[part 3 of 3]
AUTOSAR XML (schema 00044)
package /Continental_08/PowerSAR/StdSrvIf_Dem_AR430_V100/ImplementationDataTypes
  10 x impl type:
    Dem_DebounceResetStatusType: compu {0=DEM_DEBOUNCE_STATUS_FREEZE, 1=DEM_DEBOUNCE_STATUS_RESET}, implementation-data-type=uint8
    Dem_DebouncingStateType: compu {1=DEM_TEMPORARILY_DEFECTIVE, 2=DEM_FINALLY_DEFECTIVE, 4=DEM_TEMPORARILY_HEALED, 8=DEM_TEST_COMPLETE, 16=DEM_DTR_UPDATE}, implementation-data-type=uint8
    Dem_DTCFormatType: compu {0=DEM_DTC_FORMAT_OBD, 1=DEM_DTC_FORMAT_UDS, 2=DEM_DTC_FORMAT_J1939}, implementation-data-type=uint8
    Dem_DTRControlType: compu {0=DEM_DTR_CTL_NORMAL, 1=DEM_DTR_CTL_NO_MAX, 2=DEM_DTR_CTL_NO_MIN, 3=DEM_DTR_CTL_RESET, 4=DEM_DTR_CTL_INVISIBLE}, implementation-data-type=uint8
    Dem_EventStatusType: compu {0=DEM_EVENT_STATUS_PASSED, 1=DEM_EVENT_STATUS_FAILED, 2=DEM_EVENT_STATUS_PREPASSED, 3=DEM_EVENT_STATUS_PREFAILED, 4=DEM_EVENT_STATUS_FDC_THRESHOLD_REACHED}, implementation-data-type=uint8
    Dem_InitMonitorReasonType: compu {1=DEM_INIT_MONITOR_CLEAR, 2=DEM_INIT_MONITOR_RESTART, 3=DEM_INIT_MONITOR_REENABLED, 4=DEM_INIT_MONITOR_STORAGE_REENABLED}, implementation-data-type=uint8
    Dem_MaxDataValueType: category=ARRAY
      element DimX: array-size=ScNrByteBufFrfDem, array-size-semantics=FIXED-SIZE, implementation-data-type=uint8
    Dem_MonitorStatusType: compu {1=DEM_MONITOR_STATUS_TF, 2=DEM_MONITOR_STATUS_TNCTOC}, implementation-data-type=uint8
    Dem_OperationCycleStateType: compu {0=DEM_CYCLE_STATE_START, 1=DEM_CYCLE_STATE_END}, implementation-data-type=uint8
    Dem_UdsStatusByteType: compu {1=DEM_UDS_STATUS_TF, 2=DEM_UDS_STATUS_TFTOC, 4=DEM_UDS_STATUS_PDTC, 8=DEM_UDS_STATUS_CDTC, 16=DEM_UDS_STATUS_TNCSLC, 32=DEM_UDS_STATUS_TFSLC, 64=DEM_UDS_STATUS_TNCTOC, 128=DEM_UDS_STATUS_WIR}, implementation-data-type=uint8
package /Continental_08/PowerSAR/StdSrvIf_Dem_AR430_V100/PortInterfaces/V1_0_0
  6 x client server interface, all with is-service=true:
    CallbackClearEventAllowed  # Gets the permission before clearing a specific event from the SW-C
      operation ClearEventAllowed: possible-error=[CallbackClearEventAllowed/E_NOT_OK, CallbackClearEventAllowed/E_OK]  # Gets the permission to clear a specific event
        arg Allowed: type=boolean, direction=OUT, server-argument-impl-policy=USE-ARGUMENT-TYPE  # True - clearance of event is allowed, False - clearance of event is not allowed
      error E_NOT_OK: error-code=1
      error E_OK: error-code=0
    CycleQualified  # Provides the capability to get and set the qualification state of the dependent operation cycle
      operation GetCycleQualified: possible-error=[CycleQualified/E_NOT_OK, CycleQualified/E_OK]  # Returns the qualification state of the dependent operation cycle. Always E_OK is returned.
        arg isQualified: type=boolean, direction=OUT, server-argument-impl-policy=USE-ARGUMENT-TYPE  # TRUE: The dependent operation cylcle is qualified. FALSE: The qualification conditions of the dependent operation cylcle have not been met.
      operation SetCycleQualified: possible-error=[CycleQualified/E_NOT_OK, CycleQualified/E_OK]  # Sets a dependent operation cycle as qualified, so it may be processed along with its leading cycle. Always E_OK is returned.
      error E_NOT_OK: error-code=1
      error E_OK: error-code=0
    DTRCentralReport  # Provides the capability to report a DTR result
      operation SetDTR: possible-error=[DTRCentralReport/E_NOT_OK, DTRCentralReport/E_OK]  # Reports a DTR result with lower and upper limit. E_NOT_OK: Report of DTR result failed
        4 x arg, all with direction=IN, server-argument-impl-policy=USE-ARGUMENT-TYPE:
          TestResult: type=sint32  # Test result of DTR
          LowerLimit: type=sint32  # Lower limit of DTR
          UpperLimit: type=sint32  # Upper limit of DTR
          Ctrlval: type=Dem_DTRControlType  # Control value of the DTR to support its interpretation Dem-internally
      error E_NOT_OK: error-code=1
      error E_OK: error-code=0
    EnableCondition  # Provides the capability to set an enable condition
      operation SetEnableCondition: possible-error=[EnableCondition/E_NOT_OK, EnableCondition/E_OK]  # Sets an enable condition. E_NOT_OK: the setting of the enable condition failed
        arg ConditionFulfilled: type=boolean, direction=IN, server-argument-impl-policy=USE-ARGUMENT-TYPE  # Specifies whether the enable condition is fulfilled (TRUE) or not fulfilled (FALSE)
      error E_NOT_OK: error-code=1
      error E_OK: error-code=0
    EventAvailable  # Provides the capability to control the available status of an event
      operation SetEventAvailable: possible-error=[EventAvailable/E_NOT_OK, EventAvailable/E_OK]  # Set the available status of a specific event. E_NOT_OK: change of available status not accepted
        arg AvailableStatus: type=boolean, direction=IN, server-argument-impl-policy=USE-ARGUMENT-TYPE  # Specifies whether the respective event shall be available (TRUE) or not (FALSE)
      error E_NOT_OK: error-code=1
      error E_OK: error-code=0
    OperationCycle  # Provides the capability to set the state of an operation cycle
      operation GetOperationCycleState: possible-error=[OperationCycle/E_NOT_OK, OperationCycle/E_OK]  # Gets information about the status of a specific operation cycle
        arg CycleState: type=Dem_OperationCycleStateType, direction=OUT, server-argument-impl-policy=USE-ARGUMENT-TYPE  # Cycle status information
      operation SetOperationCycleState: possible-error=[OperationCycle/E_NOT_OK, OperationCycle/E_OK]  # Sets an operation cycle state. The interface has an asynchronous behavior. The asynchronous acknowledgements are the related InitMonitorForEvent callbacks.
        arg CycleState: type=Dem_OperationCycleStateType, direction=IN, server-argument-impl-policy=USE-ARGUMENT-TYPE  # New operation cycle state: (re-)start or end
      error E_NOT_OK: error-code=1
      error E_OK: error-code=0
package /Continental_08/PowerSAR/StdSrvIf_Dem_AR430_V100/PortInterfaces/V2_0_0
  5 x client server interface, all with is-service=true:
    CallbackGetFaultDetectCounter  # Gets the monitor-internal fault detection counter value of a specific event from the SW-C
      operation GetFaultDetectionCounter: possible-error=[CallbackGetFaultDetectCounter/E_NOT_OK, CallbackGetFaultDetectCounter/E_OK]  # Gets the current fault detection counter value
        arg FaultDetectionCounter: type=sint8, direction=OUT, server-argument-impl-policy=USE-ARGUMENT-TYPE  # This parameter receives the fault detection counter information of the requested EventId. If the return value of the function call is other than E_OK this parameter does not contain valid data. Range: -128...127 PASSED...FAILED according to ISO 14229-1
      error E_NOT_OK: error-code=1
      error E_OK: error-code=0
    CallbackInitMonitorForEvent  # Triggers an event-specific initialization of the monitor part of the SW-C
      operation InitMonitorForEvent: possible-error=[CallbackInitMonitorForEvent/E_NOT_OK, CallbackInitMonitorForEvent/E_OK]  # Initializes the diagnostic monitor of a specific event. Return value shall be always E_OK.
        arg InitMonitorReason: type=Dem_InitMonitorReasonType, direction=IN, server-argument-impl-policy=USE-ARGUMENT-TYPE  # Specific (re-)initialization reason evaluated from the monitor to identify the initialization kind to be performed
      error E_NOT_OK: error-code=1
      error E_OK: error-code=0
    DiagnosticMonitor  # Provides the capability to modify the event information
      6 x operation, all with possible-error=[DiagnosticMonitor/E_NOT_OK, DiagnosticMonitor/E_OK]:
        ClearPrestoredFreezeFrame  # Clears a prestored freeze frame of a specific event.
        PrestoreFreezeFrame  # Captures the freeze frame data for a specific event.
        ResetEventDebounceStatus  # Controls the internal debounce counter/timer. The event qualification will not be affected by these debounce state changes. E_NOT_OK: Only on development error
          arg DebounceResetStatus: type=Dem_DebounceResetStatusType, direction=IN, server-argument-impl-policy=USE-ARGUMENT-TYPE  # Freeze or reset the internal debounce counter/timer of the specified event
        ResetEventStatus  # Resets the event failed status. E_NOT_OK: reset of event status failed or is not allowed, because the event is already tested in this operation cycle
        SetEventDisabled  # Service for reporting the event as disabled to the Dem for the PID $41 computation.
        SetEventStatus  # Processes the events reported by SW-Cs via RTE. E_NOT_OK: set of event status failed or could not be accepted (e.g.: the operation cycle configured for this event has not been started, an according enable condition has been disabled)
          arg EventStatus: type=Dem_EventStatusType, direction=IN, server-argument-impl-policy=USE-ARGUMENT-TYPE  # Monitor test result
      error E_NOT_OK: error-code=1
      error E_OK: error-code=0
    IUMPRDenominator  # Provides the capability to define the number of times the vehicle operation has been fulfilled
      operation RepIUMPRDenLock: possible-error=[IUMPRDenominator/E_NOT_OK, IUMPRDenominator/E_OK]  # Service is used to lock a denominator of a specific monitor.
      operation RepIUMPRDenRelease: possible-error=[IUMPRDenominator/E_NOT_OK, IUMPRDenominator/E_OK]  # Service is used to release a denominator of a specific monitor.
      error E_NOT_OK: error-code=1
      error E_OK: error-code=0
    IUMPRNumerator  # Provides the capability to define the number of times a fault could have been found
      operation RepIUMPRFaultDetect: possible-error=[IUMPRNumerator/E_NOT_OK, IUMPRNumerator/E_OK]  # Service for reporting that faults are possibly found because all conditions are fullfilled.
      error E_NOT_OK: error-code=1
      error E_OK: error-code=0
package /Continental_08/PowerSAR/StdSrvIf_Dem_AR430_V100/PortInterfaces/V3_0_0
  client server interface DiagnosticInfo: is-service=true  # Provides the capability to obtain the event information
    7 x operation:
      GetDebouncingOfEvent: possible-error=[DiagnosticInfo/E_NOT_OK, DiagnosticInfo/E_OK]  # Gets the debouncing status of an event. This function shall not be used for events with native debouncing within their functions. It is rather for events using debouncing within the Dem.
        arg DebouncingState: type=Dem_DebouncingStateType, direction=OUT, server-argument-impl-policy=USE-ARGUMENT-TYPE  # Bit 0 temporarily defective (0 < FDC < 127), Bit 1 finally defective (FDC = 127), Bit 2 temporarily healed (-128 < FDC < 0), Bit 3 test complete (FDC = -128 or 127), Bit 4 DTR update (test && debouncing complete && enable/storage conditions fulfilled)
      GetDTCOfEvent: possible-error=[DEM_E_NO_DTC_AVAILABLE, DiagnosticInfo/E_NOT_OK, DiagnosticInfo/E_OK]  # Gets the DTC of an event. DEM_E_NO_DTC_AVAILABLE: there is no DTC configured in the requested format
        arg DTCFormat: type=Dem_DTCFormatType, direction=IN, server-argument-impl-policy=USE-ARGUMENT-TYPE  # Defines the output-format of the requested DTC value
        arg DTCOfEvent: type=uint32, direction=OUT, server-argument-impl-policy=USE-ARGUMENT-TYPE  # Receives the DTC value in respective format returned by this function. If the return value of the function is other than E_OK this parameter does not contain valid data.
      GetEventExtendedDataRecordEx: possible-error=[DEM_BUFFER_TOO_SMALL, DEM_NO_SUCH_ELEMENT, DiagnosticInfo/E_NOT_OK, DiagnosticInfo/E_OK]  # Gets the data of an extended data record by event. DEM_BUFFER_TOO_SMALL: The provided buffer size is too small. DEM_NO_SUCH_ELEMENT: The requested event data is not currently stored or the requested record number is not supported by the event or the requested DID is not supported by the freeze frame.
        arg RecordNumber: type=uint8, direction=IN, server-argument-impl-policy=USE-ARGUMENT-TYPE  # Identification of requested Extended data record. Valid values are between 0x01 and 0xEF as defined in ISO14229-1.
        arg DestBuffer: type=Dem_MaxDataValueType, direction=OUT, server-argument-impl-policy=USE-ARRAY-BASE-TYPE  # This parameter contains a byte pointer that points to the buffer, to which the extended data shall be written to. The format is raw hexadecimal values and contains no header-information.
        arg BufSize: type=uint16, direction=INOUT, server-argument-impl-policy=USE-ARGUMENT-TYPE  # When the function is called this parameter contains the maximum number of data bytes that can be written to the buffer. The function returns the actual number of written data bytes in this parameter.
      GetEventFreezeFrameDataEx: possible-error=[DEM_BUFFER_TOO_SMALL, DEM_NO_SUCH_ELEMENT, DiagnosticInfo/E_NOT_OK, DiagnosticInfo/E_OK]  # Gets the data of a freeze frame by event. DEM_BUFFER_TOO_SMALL: The provided buffer size is too small. DEM_NO_SUCH_ELEMENT: The requested event data is not currently stored or the requested record number is not supported by the event or the requested DID is not supported by the freeze frame.
        4 x arg:
          RecordNumber: type=uint8, direction=IN, server-argument-impl-policy=USE-ARGUMENT-TYPE  # This parameter is a unique identifier for a freeze frame record as defined in ISO14229-1. 0xFF means most recent freeze frame record is returned. 0x00 is only supported if the Dem module supports WWH-OBD.
          DataId: type=uint16, direction=IN, server-argument-impl-policy=USE-ARGUMENT-TYPE  # This parameter specifies the DID (ISO14229-1) that shall be copied to the destination buffer.
          DestBuffer: type=Dem_MaxDataValueType, direction=OUT, server-argument-impl-policy=USE-ARRAY-BASE-TYPE  # This parameter contains a byte pointer that points to the buffer, to which the freeze frame data record shall be written to. The format is raw hexadecimal values and contains no header-information.
          BufSize: type=uint16, direction=INOUT, server-argument-impl-policy=USE-ARGUMENT-TYPE  # When the function is called this parameter contains the maximum number of data bytes that can be written to the buffer. The function returns the actual number of written data bytes in this parameter.
      GetEventUdsStatus: possible-error=[DiagnosticInfo/E_NOT_OK, DiagnosticInfo/E_OK]  # Gets the current UDS status byte assigned to the DTC for the event
        arg UDSStatusByte: type=Dem_UdsStatusByteType, direction=OUT, server-argument-impl-policy=USE-ARGUMENT-TYPE  # UDS DTC status byte of the requested event. If the return value of the function call is E_NOT_OK, this parameter does not contain valid data.
      GetFaultDetectionCounter: possible-error=[DEM_E_NO_FDC_AVAILABLE, DiagnosticInfo/E_NOT_OK, DiagnosticInfo/E_OK]  # Gets the current fault detection counter value. DEM_E_NO_FDC_AVAILABLE: there is no fault detection counter available for the requested event.
        arg FaultDetectionCounter: type=sint8, direction=OUT, server-argument-impl-policy=USE-ARGUMENT-TYPE  # This parameter receives the fault detection counter information of the requested EventId. If the return value of the function call is other than E_OK this parameter does not contain valid data. Range: -128...127 PASSED...FAILED according to ISO 14229-1
      GetMonitorStatus: possible-error=[DiagnosticInfo/E_NOT_OK, DiagnosticInfo/E_OK]  # Gets the current monitor status for an event. E_NOT_OK: getting the monitor status failed (e.g. an invalid event id was provided).
        arg MonitorStatus: type=Dem_MonitorStatusType, direction=OUT, server-argument-impl-policy=USE-ARGUMENT-TYPE  # Monitor status byte of the requested event. If the return value of the function call is E_NOT_OK, this parameter does not contain valid data.
    6 x error:
      DEM_BUFFER_TOO_SMALL: error-code=21
      DEM_E_NO_DTC_AVAILABLE: error-code=10
      DEM_E_NO_FDC_AVAILABLE: error-code=14
      DEM_NO_SUCH_ELEMENT: error-code=48
      E_NOT_OK: error-code=1
      E_OK: error-code=0
package /Continental_08/PowerSAR/StdSrvIf_FiM_AR422_V100/PortInterfaces/V2_0_0
  client server interface FunctionInhibition: is-service=true  # Service to query for the permission to execute a certain functionality represented by a FID.
    operation GetFunctionPermission: possible-error=[FunctionInhibition/E_NOT_OK, FunctionInhibition/E_OK]  # Get the permission state of the respective FID. E_NOT_OK: The request is not accepted, ie. initialization of FIM not completed
      arg Permission: type=boolean, direction=OUT, server-argument-impl-policy=USE-ARGUMENT-TYPE  # The permission of the requested FID. TRUE: FID has permission to run. FALSE: FID has no permission to run, i.e. shall not be executed.
    error E_NOT_OK: error-code=1
    error E_OK: error-code=0
package /Continental_08/PowerSAR/StdSrvIf_NvM_AR422_V100/ImplementationDataTypes
  impl type NvM_RequestResultType: compu {0=NVM_REQ_OK, 1=NVM_REQ_NOT_OK, 2=NVM_REQ_PENDING, 3=NVM_REQ_INTEGRITY_FAILED, 4=NVM_REQ_BLOCK_SKIPPED, 5=NVM_REQ_NV_INVALIDATED, 6=NVM_REQ_CANCELED, 7=NVM_REQ_REDUNDANCY_FAILED, 8=NVM_REQ_RESTORED_FROM_ROM}, implementation-data-type=uint8
package /Continental_08/PowerSAR/StdSrvIf_NvM_AR422_V100/PortInterfaces/V2_0_0
  client server interface NvMNotifyInitBlock  # Callback that is called by the NvM module when default data needs to be restored to the RAM image
    operation InitBlock: possible-error=NvMNotifyInitBlock/E_OK  # This callback is called if the initialization of a block has completed.
    error E_OK: error-code=0
  client server interface NvMNotifyJobFinished  # Callback that is called when a job has finished
    operation JobFinished: possible-error=NvMNotifyJobFinished/E_OK  # Callback that gets called if a job has finished
      arg ServiceId: type=uint8, direction=IN, server-argument-impl-policy=USE-ARGUMENT-TYPE  # Unique Service ID of NVRAM manager service
      arg JobResult: type=NvM_RequestResultType, direction=IN, server-argument-impl-policy=USE-ARGUMENT-TYPE  # Covers the job result of the previous processed single block job
    error E_OK: error-code=0
  client server interface NvMService  # The NvMService interface provides all main single block operations.
    12 x operation, all with possible-error=[NvMService/E_NOT_OK, NvMService/E_OK]:
      EraseBlock  # Service to erase a NV block.
      GetDataIndex  # Service for getting the currently set DataIndex of a dataset NVRAM block.
        arg DataIndexPtr: type=uint8, direction=OUT, server-argument-impl-policy=USE-ARGUMENT-TYPE  # Pointer to where to store the current dataset index (0..255)
      GetErrorStatus  # Service to read the block dependent error status information.
        arg RequestResultPtr: type=NvM_RequestResultType, direction=OUT, server-argument-impl-policy=USE-ARGUMENT-TYPE  # Pointer to where to store the request result
      InvalidateNvBlock  # Service to invalidate a NV block.
      ReadBlock  # Service to copy the data of the NV block to its corresponding RAM block.
        arg DstPtr: type=VoidPtr, direction=IN, server-argument-impl-policy=USE-ARGUMENT-TYPE  # Pointer to the RAM data block. It shall be set to NULL_PTR, if the RAM block is managed by the RTE through a NvBlockSwComponent.
      ReadPRAMBlock  # Service to copy the data of the NV block to its corresponding RAM block.
      RestoreBlockDefaults  # Service to restore the default data to its corresponding RAM block.
        arg DstPtr: type=VoidPtr, direction=IN, server-argument-impl-policy=USE-ARGUMENT-TYPE  # Pointer to the RAM data block. It shall be set to NULL_PTR, if the RAM block is managed by the RTE through a NvBlockSwComponent.
      RestorePRAMBlockDefaults  # Service to restore the default data to its corresponding RAM block.
      SetDataIndex  # Service for setting the DataIndex of a dataset NVRAM block.
        arg DataIndex: type=uint8, direction=IN, server-argument-impl-policy=USE-ARGUMENT-TYPE  # Index position (association) of a NV or ROM block
      SetRamBlockStatus  # Service for setting the RAM block status of an NVRAM block.
        arg BlockChanged: type=boolean, direction=IN, server-argument-impl-policy=USE-ARGUMENT-TYPE  # TRUE - validate the RAM block and mark block as changed, FALSE - invalidate the RAM block and mark block as unchanged
      WriteBlock  # Service to copy the data of the RAM block to its corresponding NV block.
        arg SrcPtr: type=ConstVoidPtr, direction=IN, server-argument-impl-policy=USE-ARGUMENT-TYPE  # Pointer to the RAM data block. It shall be set to NULL_PTR, if the RAM block is managed by the RTE through a NvBlockSwComponent.
      WritePRAMBlock  # Service to copy the data of the RAM block to its corresponding NV block.
    error E_NOT_OK: error-code=1
    error E_OK: error-code=0
package /Continental_08/PowerSAR/StdSrvIf_WdgM_AR430_V100/ImplementationDataTypes
  impl type WdgM_LocalStatusType: compu {0=WDGM_LOCAL_STATUS_OK, 1=WDGM_LOCAL_STATUS_FAILED, 2=WDGM_LOCAL_STATUS_EXPIRED, 4=WDGM_LOCAL_STATUS_DEACTIVATED}, implementation-data-type=uint8
package /Continental_08/PowerSAR/StdSrvIf_WdgM_AR430_V100/PortInterfaces/V1_0_0
  client server interface WdgM_LocalSupervision: is-service=true  # Supervision interface of one supervised entity checkpoint
    operation CheckpointReached: possible-error=[WdgM_LocalSupervision/E_NOT_OK, WdgM_LocalSupervision/E_OK]  # Indicates to the Watchdog Manager that a Checkpoint within a Supervised Entity has been reached
    error E_NOT_OK: error-code=1
    error E_OK: error-code=0
  client server interface WdgM_LocalSupervisionStatus: is-service=true  # Supervision status interface of one supervised entity
    operation GetLocalStatus: possible-error=[WdgM_LocalSupervisionStatus/E_NOT_OK, WdgM_LocalSupervisionStatus/E_OK]  # Returns the supervision status of an individual Supervised Entity
      arg Status: type=WdgM_LocalStatusType, direction=OUT, server-argument-impl-policy=USE-ARGUMENT-TYPE  # Supervision status of the given supervised entity
    error E_NOT_OK: error-code=1
    error E_OK: error-code=0
package /Continental_08/PowerSAR/Pcpt_BPL2AR  # Adaptation module for bus communication in receive direction
  complex device driver sw component type BPL2AR  # Adaptation module for bus communication in receive direction
    24 x provide/require port:
      PR_FacKpTqEmDynAjExt: nonqueued-sender-com-spec{data-element=FacKpTqEmDynAjExt, init-value=0 Nm*s}, provided-required-interface=FacKpTqEmDynAjExt  # External amplification factor for dynamic electrical machine torque path of anti-jerk
      PR_LvAjActExt: nonqueued-sender-com-spec{data-element=LvAjActExt, init-value=FALSE}, provided-required-interface=LvAjActExt  # External anti-jerk active
      PR_LvSleepReqVeh: nonqueued-sender-com-spec{data-element=LvSleepReqVeh, init-value=FALSE}, provided-required-interface=LvSleepReqVeh  # Sleep requested from vehicle
      PR_LvStOpmEmCtlNActReqClu: nonqueued-sender-com-spec{data-element=LvStOpmEmCtlNActReqClu, init-value=FALSE}, provided-required-interface=LvStOpmEmCtlNActReqClu  # Clutch is requesting to activate speed control
      PR_LvStOpmEmCtlTqActReqClu: nonqueued-sender-com-spec{data-element=LvStOpmEmCtlTqActReqClu, init-value=FALSE}, provided-required-interface=LvStOpmEmCtlTqActReqClu  # Clutch is requesting to activate torque control
      PR_LvUHvsReqExtEna: nonqueued-sender-com-spec{data-element=LvUHvsReqExtEna, init-value=FALSE}, provided-required-interface=LvUHvsReqExtEna  # External request to enable high voltage
      PR_NEmOscAjThdExt: nonqueued-sender-com-spec{data-element=NEmOscAjThdExt, init-value=0 1/s}, provided-required-interface=NEmOscAjThdExt  # External electrical machine speed oscillation threshold for anti-jerk
      PR_NEmReqClu: nonqueued-sender-com-spec{data-element=NEmReqClu, init-value=0 1/s}, provided-required-interface=NEmReqClu  # Electrical machine torque requested from clutch control
      PR_NEmReqExtMain: nonqueued-sender-com-spec{data-element=NEmReqExtMain, init-value=0 1/s}, provided-required-interface=NEmReqExtMain  # Electrical machine speed requested by main external function
      PR_StOpmCluEm: nonqueued-sender-com-spec{data-element=StOpmCluEm, init-value=INI}, provided-required-interface=StOpmCluEm  # Operational state of electrical machine clutch
      PR_StOpmEmReqMain: nonqueued-sender-com-spec{data-element=StOpmEmReqMain, init-value=0}, provided-required-interface=StOpmEmReqMain  # Electrical machine state requested by main external function
      PR_StSelTqEmLimReq: nonqueued-sender-com-spec{data-element=StSelTqEmLimReq, init-value=EXT}, provided-required-interface=StSelTqEmLimReq  # State of electric machine torque limitation selection according to ACU control
      PR_TqEmMaxReqAj: nonqueued-sender-com-spec{data-element=TqEmMaxReqAj, init-value=0 Nm}, provided-required-interface=TqEmMaxReqAj  # Requested maximum electric machine torque limit for anti-jerk
      PR_TqEmMinReqAj: nonqueued-sender-com-spec{data-element=TqEmMinReqAj, init-value=0 Nm}, provided-required-interface=TqEmMinReqAj  # Requested minimum electric machine torque limit for anti-jerk
      PR_TqEmReqClu: nonqueued-sender-com-spec{data-element=TqEmReqClu, init-value=0 Nm}, provided-required-interface=TqEmReqClu  # Electrical machine torque requested by clutch
      PR_TqEmReqCluMax: nonqueued-sender-com-spec{data-element=TqEmReqCluMax, init-value=0 Nm}, provided-required-interface=TqEmReqCluMax  # Maximum electrical machine torque requested from clutch control
      PR_TqEmReqCluMin: nonqueued-sender-com-spec{data-element=TqEmReqCluMin, init-value=0 Nm}, provided-required-interface=TqEmReqCluMin  # Minimum electrical machine torque requested from clutch control
      PR_TqEmReqExtMain: nonqueued-sender-com-spec{data-element=TqEmReqExtMain, init-value=0 Nm}, provided-required-interface=TqEmReqExtMain  # Electrical machine torque requested by main external function
      PR_TqEmReqExtMainMax: nonqueued-sender-com-spec{data-element=TqEmReqExtMainMax, init-value=0 Nm}, provided-required-interface=TqEmReqExtMainMax  # Maximum electrical machine torque requested by main external function
      PR_TqEmReqExtMainMin: nonqueued-sender-com-spec{data-element=TqEmReqExtMainMin, init-value=0 Nm}, provided-required-interface=TqEmReqExtMainMin  # Minimum electrical machine torque requested by main external function
      PR_TWtrCoolInExt: nonqueued-sender-com-spec{data-element=TWtrCoolInExt, init-value=0 K}, provided-required-interface=TWtrCoolInExt  # Inlet water coolant temperature from external source
      PR_ValRawIHvsDcvMaxReqPred: nonqueued-sender-com-spec{data-element=ValRawIHvsDcvMaxReqPred, init-value=0}, provided-required-interface=ValRawIHvsDcvMaxReqPred  # Signal representing predicted maximum DC link current coming from the communication
      PR_ValRawIHvsDcvMinReqPred: nonqueued-sender-com-spec{data-element=ValRawIHvsDcvMinReqPred, init-value=0}, provided-required-interface=ValRawIHvsDcvMinReqPred  # Signal representing predicted minimum DC link current coming from the communication
      PR_VfCool: nonqueued-sender-com-spec{data-element=VfCool, init-value=0 (m^3)/s}, provided-required-interface=VfCool  # Coolant volume flow
    behavior BPL2AR: constant-value-mapping=BPL2AR_DefaultConstantMapping, data-type-mapping=DefaultDataTypeMapping, handle-termination-and-restart=NO-SUPPORT
      included-data-type-sets:
        data-type=Boolean, literal-prefix=Boolean_
        data-type=TxtStOpmCluEm2, literal-prefix=TxtStOpmCluEm2_
        data-type=TxtStSelTqEmLim, literal-prefix=TxtStSelTqEmLim_
      runnable BPL2AR_ClcDataComAdp: sw-addr-method=CODE_10MS_QM
        data-write-access:
          24 x access:
            PR_FacKpTqEmDynAjExt_FacKpTqEmDynAjExt_Wr: accessed-variable=PR_FacKpTqEmDynAjExt.FacKpTqEmDynAjExt
            PR_LvAjActExt_LvAjActExt_Wr: accessed-variable=PR_LvAjActExt.LvAjActExt
            PR_LvSleepReqVeh_LvSleepReqVeh_Wr: accessed-variable=PR_LvSleepReqVeh.LvSleepReqVeh
            PR_LvStOpmEmCtlNActReqClu_LvStOpmEmCtlNActReqClu_Wr: accessed-variable=PR_LvStOpmEmCtlNActReqClu.LvStOpmEmCtlNActReqClu
            PR_LvStOpmEmCtlTqActReqClu_LvStOpmEmCtlTqActReqClu_Wr: accessed-variable=PR_LvStOpmEmCtlTqActReqClu.LvStOpmEmCtlTqActReqClu
            PR_LvUHvsReqExtEna_LvUHvsReqExtEna_Wr: accessed-variable=PR_LvUHvsReqExtEna.LvUHvsReqExtEna
            PR_NEmOscAjThdExt_NEmOscAjThdExt_Wr: accessed-variable=PR_NEmOscAjThdExt.NEmOscAjThdExt
            PR_NEmReqClu_NEmReqClu_Wr: accessed-variable=PR_NEmReqClu.NEmReqClu
            PR_NEmReqExtMain_NEmReqExtMain_Wr: accessed-variable=PR_NEmReqExtMain.NEmReqExtMain
            PR_StOpmCluEm_StOpmCluEm_Wr: accessed-variable=PR_StOpmCluEm.StOpmCluEm
            PR_StOpmEmReqMain_StOpmEmReqMain_Wr: accessed-variable=PR_StOpmEmReqMain.StOpmEmReqMain
            PR_StSelTqEmLimReq_StSelTqEmLimReq_Wr: accessed-variable=PR_StSelTqEmLimReq.StSelTqEmLimReq
            PR_TqEmMaxReqAj_TqEmMaxReqAj_Wr: accessed-variable=PR_TqEmMaxReqAj.TqEmMaxReqAj
            PR_TqEmMinReqAj_TqEmMinReqAj_Wr: accessed-variable=PR_TqEmMinReqAj.TqEmMinReqAj
            PR_TqEmReqClu_TqEmReqClu_Wr: accessed-variable=PR_TqEmReqClu.TqEmReqClu
            PR_TqEmReqCluMax_TqEmReqCluMax_Wr: accessed-variable=PR_TqEmReqCluMax.TqEmReqCluMax
            PR_TqEmReqCluMin_TqEmReqCluMin_Wr: accessed-variable=PR_TqEmReqCluMin.TqEmReqCluMin
            PR_TqEmReqExtMain_TqEmReqExtMain_Wr: accessed-variable=PR_TqEmReqExtMain.TqEmReqExtMain
            PR_TqEmReqExtMainMax_TqEmReqExtMainMax_Wr: accessed-variable=PR_TqEmReqExtMainMax.TqEmReqExtMainMax
            PR_TqEmReqExtMainMin_TqEmReqExtMainMin_Wr: accessed-variable=PR_TqEmReqExtMainMin.TqEmReqExtMainMin
            PR_TWtrCoolInExt_TWtrCoolInExt_Wr: accessed-variable=PR_TWtrCoolInExt.TWtrCoolInExt
            PR_ValRawIHvsDcvMaxReqPred_ValRawIHvsDcvMaxReqPred_Wr: accessed-variable=PR_ValRawIHvsDcvMaxReqPred.ValRawIHvsDcvMaxReqPred
            PR_ValRawIHvsDcvMinReqPred_ValRawIHvsDcvMinReqPred_Wr: accessed-variable=PR_ValRawIHvsDcvMinReqPred.ValRawIHvsDcvMinReqPred
            PR_VfCool_VfCool_Wr: accessed-variable=PR_VfCool.VfCool
  constant specification mapping set BPL2AR_DefaultConstantMapping
  swc implementation BPL2AR_impl: programming-language=C, vendor-id=142, behavior=BPL2AR
    code-descriptors:
      code BPL2AR: artifact-descriptors=autosar-engineering-object={short-label=BPL2AR, category=SWSRC, domain=PowerSAR}
    required-artifacts:
      dependency on artifact ecmath: artifact-descriptor={short-label=ecmath, category=SWHDR, domain=PowerSAR}
      dependency on artifact f32_math: artifact-descriptor={short-label=f32_math, category=SWHDR, domain=PowerSAR}
    resource consumption BPL2AR_rc
      memory section CODE_10MS_QM: sw-addrmethod=CODE_10MS_QM
  swc timing BPL2AR_Timing: behavior=BPL2AR
    timing-guarantees:
      execution order constraint BPL2AR_ClcDataComAdp_SysTrig_10msT1_SEV
        ordered-elements:
          eoc executable entity ref BPL2AR_ClcDataComAdp_SysTrig_10msT1_SEV: executable=BPL2AR_ClcDataComAdp
          eoc executable entity ref group BPL2AR_ClcDataComAdp_SysTrig_10msT1_SEV_Grp: nested-element=BPL2AR_ClcDataComAdp_SysTrig_10msT1_SEV, triggering-event=SysTrig_10msT1/SEV
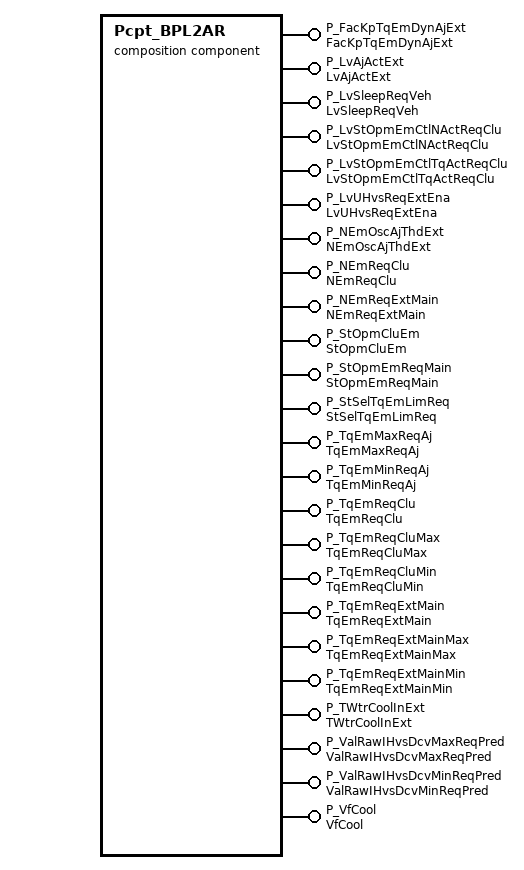
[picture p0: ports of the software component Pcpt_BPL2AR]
  composition sw component type Pcpt_BPL2AR: data-type-mapping=DefaultDataTypeMapping  # Adaptation module for bus communication in receive direction
    24 x provide port:
      P_FacKpTqEmDynAjExt: provided-interface=FacKpTqEmDynAjExt  # External amplification factor for dynamic electrical machine torque path of anti-jerk
      P_LvAjActExt: provided-interface=LvAjActExt  # External anti-jerk active
      P_LvSleepReqVeh: provided-interface=LvSleepReqVeh  # Sleep requested from vehicle
      P_LvStOpmEmCtlNActReqClu: provided-interface=LvStOpmEmCtlNActReqClu  # Clutch is requesting to activate speed control
      P_LvStOpmEmCtlTqActReqClu: provided-interface=LvStOpmEmCtlTqActReqClu  # Clutch is requesting to activate torque control
      P_LvUHvsReqExtEna: provided-interface=LvUHvsReqExtEna  # External request to enable high voltage
      P_NEmOscAjThdExt: provided-interface=NEmOscAjThdExt  # External electrical machine speed oscillation threshold for anti-jerk
      P_NEmReqClu: provided-interface=NEmReqClu  # Electrical machine torque requested from clutch control
      P_NEmReqExtMain: provided-interface=NEmReqExtMain  # Electrical machine speed requested by main external function
      P_StOpmCluEm: provided-interface=StOpmCluEm  # Operational state of electrical machine clutch
      P_StOpmEmReqMain: provided-interface=StOpmEmReqMain  # Electrical machine state requested by main external function
      P_StSelTqEmLimReq: provided-interface=StSelTqEmLimReq  # State of electric machine torque limitation selection according to ACU control
      P_TqEmMaxReqAj: provided-interface=TqEmMaxReqAj  # Requested maximum electric machine torque limit for anti-jerk
      P_TqEmMinReqAj: provided-interface=TqEmMinReqAj  # Requested minimum electric machine torque limit for anti-jerk
      P_TqEmReqClu: provided-interface=TqEmReqClu  # Electrical machine torque requested by clutch
      P_TqEmReqCluMax: provided-interface=TqEmReqCluMax  # Maximum electrical machine torque requested from clutch control
      P_TqEmReqCluMin: provided-interface=TqEmReqCluMin  # Minimum electrical machine torque requested from clutch control
      P_TqEmReqExtMain: provided-interface=TqEmReqExtMain  # Electrical machine torque requested by main external function
      P_TqEmReqExtMainMax: provided-interface=TqEmReqExtMainMax  # Maximum electrical machine torque requested by main external function
      P_TqEmReqExtMainMin: provided-interface=TqEmReqExtMainMin  # Minimum electrical machine torque requested by main external function
      P_TWtrCoolInExt: provided-interface=TWtrCoolInExt  # Inlet water coolant temperature from external source
      P_ValRawIHvsDcvMaxReqPred: provided-interface=ValRawIHvsDcvMaxReqPred  # Signal representing predicted maximum DC link current coming from the communication
      P_ValRawIHvsDcvMinReqPred: provided-interface=ValRawIHvsDcvMinReqPred  # Signal representing predicted minimum DC link current coming from the communication
      P_VfCool: provided-interface=VfCool  # Coolant volume flow
    component BPL2AR: type=BPL2AR
    delegate BPL2AR.PR_FacKpTqEmDynAjExt <-> outer port P_FacKpTqEmDynAjExt
    delegate BPL2AR.PR_LvAjActExt <-> outer port P_LvAjActExt
    delegate BPL2AR.PR_LvSleepReqVeh <-> outer port P_LvSleepReqVeh
    delegate BPL2AR.PR_LvStOpmEmCtlNActReqClu <-> outer port P_LvStOpmEmCtlNActReqClu
    delegate BPL2AR.PR_LvStOpmEmCtlTqActReqClu <-> outer port P_LvStOpmEmCtlTqActReqClu
    delegate BPL2AR.PR_LvUHvsReqExtEna <-> outer port P_LvUHvsReqExtEna
    delegate BPL2AR.PR_NEmOscAjThdExt <-> outer port P_NEmOscAjThdExt
    delegate BPL2AR.PR_NEmReqClu <-> outer port P_NEmReqClu
    delegate BPL2AR.PR_NEmReqExtMain <-> outer port P_NEmReqExtMain
    delegate BPL2AR.PR_StOpmCluEm <-> outer port P_StOpmCluEm
    delegate BPL2AR.PR_StOpmEmReqMain <-> outer port P_StOpmEmReqMain
    delegate BPL2AR.PR_StSelTqEmLimReq <-> outer port P_StSelTqEmLimReq
    delegate BPL2AR.PR_TqEmMaxReqAj <-> outer port P_TqEmMaxReqAj
    delegate BPL2AR.PR_TqEmMinReqAj <-> outer port P_TqEmMinReqAj
    delegate BPL2AR.PR_TqEmReqClu <-> outer port P_TqEmReqClu
    delegate BPL2AR.PR_TqEmReqCluMax <-> outer port P_TqEmReqCluMax
    delegate BPL2AR.PR_TqEmReqCluMin <-> outer port P_TqEmReqCluMin
    delegate BPL2AR.PR_TqEmReqExtMain <-> outer port P_TqEmReqExtMain
    delegate BPL2AR.PR_TqEmReqExtMainMax <-> outer port P_TqEmReqExtMainMax
    delegate BPL2AR.PR_TqEmReqExtMainMin <-> outer port P_TqEmReqExtMainMin
    delegate BPL2AR.PR_TWtrCoolInExt <-> outer port P_TWtrCoolInExt
    delegate BPL2AR.PR_ValRawIHvsDcvMaxReqPred <-> outer port P_ValRawIHvsDcvMaxReqPred
    delegate BPL2AR.PR_ValRawIHvsDcvMinReqPred <-> outer port P_ValRawIHvsDcvMinReqPred
    delegate BPL2AR.PR_VfCool <-> outer port P_VfCool
package /Continental_08/PowerSAR/MemMap/SwAddrMethods
  457 x sw addr method:
    CALIB_ASIL_A: memory-allocation-keyword-policy=ADDR-METHOD-SHORT-NAME-AND-ALIGNMENT, options=[powersarAsw, safetyAsilA, coreGlobal, powersarBsw], section-type=CALPRM  # Calibration parameters
    CALIB_ASIL_B: memory-allocation-keyword-policy=ADDR-METHOD-SHORT-NAME-AND-ALIGNMENT, options=[powersarAsw, safetyAsilB, coreGlobal, powersarBsw], section-type=CALPRM  # Calibration parameters
    CALIB_ASIL_C: memory-allocation-keyword-policy=ADDR-METHOD-SHORT-NAME-AND-ALIGNMENT, options=[safetyAsilC, powersarAsw, coreGlobal, powersarBsw], section-type=CALPRM  # Calibration parameters
    CALIB_ASIL_D: memory-allocation-keyword-policy=ADDR-METHOD-SHORT-NAME-AND-ALIGNMENT, options=[powersarAsw, safetyAsilD, coreGlobal, powersarBsw], section-type=CALPRM  # Calibration parameters
    CALIB_MAP_ASIL_A: memory-allocation-keyword-policy=ADDR-METHOD-SHORT-NAME, options=[powersarCompoundPrimitive, powersarAsw, safetyAsilA, coreGlobal, powersarBsw], section-type=CALPRM  # Calibration maps and axes (compound primitives)
    CALIB_MAP_ASIL_B: memory-allocation-keyword-policy=ADDR-METHOD-SHORT-NAME, options=[powersarCompoundPrimitive, powersarAsw, safetyAsilB, coreGlobal, powersarBsw], section-type=CALPRM  # Calibration maps and axes (compound primitives)
    CALIB_MAP_ASIL_C: memory-allocation-keyword-policy=ADDR-METHOD-SHORT-NAME, options=[powersarCompoundPrimitive, safetyAsilC, powersarAsw, coreGlobal, powersarBsw], section-type=CALPRM  # Calibration maps and axes (compound primitives)
    CALIB_MAP_ASIL_D: memory-allocation-keyword-policy=ADDR-METHOD-SHORT-NAME, options=[powersarCompoundPrimitive, powersarAsw, safetyAsilD, coreGlobal, powersarBsw], section-type=CALPRM  # Calibration maps and axes (compound primitives)
    CALIB_MAP_QM: memory-allocation-keyword-policy=ADDR-METHOD-SHORT-NAME, options=[powersarCompoundPrimitive, safetyQM, powersarAsw, coreGlobal, powersarBsw], section-type=CALPRM  # Calibration maps and axes (compound primitives)
    CALIB_OFFLINE_ASIL_A: memory-allocation-keyword-policy=ADDR-METHOD-SHORT-NAME-AND-ALIGNMENT, options=[powersarAsw, safetyAsilA, coreGlobal, offline, powersarBsw], section-type=CALPRM  # Calibration parameters to be calibrated offline only
    CALIB_OFFLINE_ASIL_B: memory-allocation-keyword-policy=ADDR-METHOD-SHORT-NAME-AND-ALIGNMENT, options=[powersarAsw, safetyAsilB, coreGlobal, offline, powersarBsw], section-type=CALPRM  # Calibration parameters to be calibrated offline only
    CALIB_OFFLINE_ASIL_C: memory-allocation-keyword-policy=ADDR-METHOD-SHORT-NAME-AND-ALIGNMENT, options=[safetyAsilC, powersarAsw, coreGlobal, offline, powersarBsw], section-type=CALPRM  # Calibration parameters to be calibrated offline only
    CALIB_OFFLINE_ASIL_D: memory-allocation-keyword-policy=ADDR-METHOD-SHORT-NAME-AND-ALIGNMENT, options=[powersarAsw, safetyAsilD, coreGlobal, offline, powersarBsw], section-type=CALPRM  # Calibration parameters to be calibrated offline only
    CALIB_OFFLINE_MAP_ASIL_A: memory-allocation-keyword-policy=ADDR-METHOD-SHORT-NAME, options=[powersarCompoundPrimitive, powersarAsw, safetyAsilA, coreGlobal, offline, powersarBsw], section-type=CALPRM  # Calibration maps and axes (compound primitives) to be calibrated offline only
    CALIB_OFFLINE_MAP_ASIL_B: memory-allocation-keyword-policy=ADDR-METHOD-SHORT-NAME, options=[powersarCompoundPrimitive, powersarAsw, safetyAsilB, coreGlobal, offline, powersarBsw], section-type=CALPRM  # Calibration maps and axes (compound primitives) to be calibrated offline only
    CALIB_OFFLINE_MAP_ASIL_C: memory-allocation-keyword-policy=ADDR-METHOD-SHORT-NAME, options=[powersarCompoundPrimitive, safetyAsilC, powersarAsw, coreGlobal, offline, powersarBsw], section-type=CALPRM  # Calibration maps and axes (compound primitives) to be calibrated offline only
    CALIB_OFFLINE_MAP_ASIL_D: memory-allocation-keyword-policy=ADDR-METHOD-SHORT-NAME, options=[powersarCompoundPrimitive, powersarAsw, safetyAsilD, coreGlobal, offline, powersarBsw], section-type=CALPRM  # Calibration maps and axes (compound primitives) to be calibrated offline only
    CALIB_OFFLINE_MAP_QM: memory-allocation-keyword-policy=ADDR-METHOD-SHORT-NAME, options=[powersarCompoundPrimitive, safetyQM, powersarAsw, coreGlobal, offline, powersarBsw], section-type=CALPRM  # Calibration maps and axes (compound primitives) to be calibrated offline only
    CALIB_OFFLINE_QM: memory-allocation-keyword-policy=ADDR-METHOD-SHORT-NAME-AND-ALIGNMENT, options=[safetyQM, powersarAsw, coreGlobal, offline, powersarBsw], section-type=CALPRM  # Calibration parameters to be calibrated offline only
    CALIB_QM: memory-allocation-keyword-policy=ADDR-METHOD-SHORT-NAME-AND-ALIGNMENT, options=[safetyQM, powersarAsw, coreGlobal, powersarBsw], section-type=CALPRM  # Calibration parameters
    CALIB_VARIANT_ASIL_A: memory-allocation-keyword-policy=ADDR-METHOD-SHORT-NAME-AND-ALIGNMENT, options=[powersarAsw, safetyAsilA, coreGlobal, powersarBsw, powersarVariant], section-type=CALPRM  # Variant specific calibration parameters
    CALIB_VARIANT_ASIL_B: memory-allocation-keyword-policy=ADDR-METHOD-SHORT-NAME-AND-ALIGNMENT, options=[powersarAsw, safetyAsilB, coreGlobal, powersarBsw, powersarVariant], section-type=CALPRM  # Variant specific calibration parameters
    CALIB_VARIANT_ASIL_C: memory-allocation-keyword-policy=ADDR-METHOD-SHORT-NAME-AND-ALIGNMENT, options=[safetyAsilC, powersarAsw, coreGlobal, powersarBsw, powersarVariant], section-type=CALPRM  # Variant specific calibration parameters
    CALIB_VARIANT_ASIL_D: memory-allocation-keyword-policy=ADDR-METHOD-SHORT-NAME-AND-ALIGNMENT, options=[powersarAsw, safetyAsilD, coreGlobal, powersarBsw, powersarVariant], section-type=CALPRM  # Variant specific calibration parameters
    CALIB_VARIANT_MAP_ASIL_A: memory-allocation-keyword-policy=ADDR-METHOD-SHORT-NAME, options=[powersarCompoundPrimitive, powersarAsw, safetyAsilA, coreGlobal, powersarBsw, powersarVariant], section-type=CALPRM  # Variant specific calibration maps and axes (compound primitives)
    CALIB_VARIANT_MAP_ASIL_B: memory-allocation-keyword-policy=ADDR-METHOD-SHORT-NAME, options=[powersarCompoundPrimitive, powersarAsw, safetyAsilB, coreGlobal, powersarBsw, powersarVariant], section-type=CALPRM  # Variant specific calibration maps and axes (compound primitives)
    CALIB_VARIANT_MAP_ASIL_C: memory-allocation-keyword-policy=ADDR-METHOD-SHORT-NAME, options=[powersarCompoundPrimitive, safetyAsilC, powersarAsw, coreGlobal, powersarBsw, powersarVariant], section-type=CALPRM  # Variant specific calibration maps and axes (compound primitives)
    CALIB_VARIANT_MAP_ASIL_D: memory-allocation-keyword-policy=ADDR-METHOD-SHORT-NAME, options=[powersarCompoundPrimitive, powersarAsw, safetyAsilD, coreGlobal, powersarBsw, powersarVariant], section-type=CALPRM  # Variant specific calibration maps and axes (compound primitives)
    CALIB_VARIANT_MAP_QM: memory-allocation-keyword-policy=ADDR-METHOD-SHORT-NAME, options=[powersarCompoundPrimitive, safetyQM, powersarAsw, coreGlobal, powersarBsw, powersarVariant], section-type=CALPRM  # Variant specific calibration maps and axes (compound primitives)
    CALIB_VARIANT_QM: memory-allocation-keyword-policy=ADDR-METHOD-SHORT-NAME-AND-ALIGNMENT, options=[safetyQM, powersarAsw, coreGlobal, powersarBsw, powersarVariant], section-type=CALPRM  # Variant specific calibration parameters
    CODE_100MS_ASIL_A: memory-allocation-keyword-policy=ADDR-METHOD-SHORT-NAME, options=[powersarAsw, safetyAsilA, powersar100ms, coreGlobal, powersarBsw], section-type=CODE  # Code called with a recurrence of 100ms or faster and global scope
    CODE_100MS_ASIL_A_LOCAL: memory-allocation-keyword-policy=ADDR-METHOD-SHORT-NAME, options=[safetyAsilA, powersar100ms, coreLocal, powersarBsw], section-type=CODE  # Code called with a recurrence of 100ms or faster and local scope
    CODE_100MS_ASIL_B: memory-allocation-keyword-policy=ADDR-METHOD-SHORT-NAME, options=[powersarAsw, safetyAsilB, powersar100ms, coreGlobal, powersarBsw], section-type=CODE  # Code called with a recurrence of 100ms or faster and global scope
    CODE_100MS_ASIL_B_LOCAL: memory-allocation-keyword-policy=ADDR-METHOD-SHORT-NAME, options=[safetyAsilB, powersar100ms, coreLocal, powersarBsw], section-type=CODE  # Code called with a recurrence of 100ms or faster and local scope
    CODE_100MS_ASIL_C: memory-allocation-keyword-policy=ADDR-METHOD-SHORT-NAME, options=[safetyAsilC, powersarAsw, powersar100ms, coreGlobal, powersarBsw], section-type=CODE  # Code called with a recurrence of 100ms or faster and global scope
    CODE_100MS_ASIL_C_LOCAL: memory-allocation-keyword-policy=ADDR-METHOD-SHORT-NAME, options=[safetyAsilC, powersar100ms, coreLocal, powersarBsw], section-type=CODE  # Code called with a recurrence of 100ms or faster and local scope
    CODE_100MS_ASIL_D: memory-allocation-keyword-policy=ADDR-METHOD-SHORT-NAME, options=[powersarAsw, safetyAsilD, powersar100ms, coreGlobal, powersarBsw], section-type=CODE  # Code called with a recurrence of 100ms or faster and global scope
    CODE_100MS_ASIL_D_LOCAL: memory-allocation-keyword-policy=ADDR-METHOD-SHORT-NAME, options=[safetyAsilD, powersar100ms, coreLocal, powersarBsw], section-type=CODE  # Code called with a recurrence of 100ms or faster and local scope
    CODE_100MS_QM: memory-allocation-keyword-policy=ADDR-METHOD-SHORT-NAME, options=[safetyQM, powersarAsw, powersar100ms, coreGlobal, powersarBsw], section-type=CODE  # Code called with a recurrence of 100ms or faster and global scope
    CODE_100MS_QM_LOCAL: memory-allocation-keyword-policy=ADDR-METHOD-SHORT-NAME, options=[safetyQM, powersar100ms, coreLocal, powersarBsw], section-type=CODE  # Code called with a recurrence of 100ms or faster and local scope
    CODE_100US_ASIL_A: memory-allocation-keyword-policy=ADDR-METHOD-SHORT-NAME, options=[powersarAsw, safetyAsilA, powersar100us, coreGlobal, powersarBsw], section-type=CODE  # Code called with a recurrence of 100us or faster and global scope
    CODE_100US_ASIL_A_LOCAL: memory-allocation-keyword-policy=ADDR-METHOD-SHORT-NAME, options=[safetyAsilA, powersar100us, coreLocal, powersarBsw], section-type=CODE  # Code called with a recurrence of 100us or faster and local scope
    CODE_100US_ASIL_B: memory-allocation-keyword-policy=ADDR-METHOD-SHORT-NAME, options=[powersarAsw, safetyAsilB, powersar100us, coreGlobal, powersarBsw], section-type=CODE  # Code called with a recurrence of 100us or faster and global scope
    CODE_100US_ASIL_B_LOCAL: memory-allocation-keyword-policy=ADDR-METHOD-SHORT-NAME, options=[safetyAsilB, powersar100us, coreLocal, powersarBsw], section-type=CODE  # Code called with a recurrence of 100us or faster and local scope
    CODE_100US_ASIL_C: memory-allocation-keyword-policy=ADDR-METHOD-SHORT-NAME, options=[safetyAsilC, powersarAsw, powersar100us, coreGlobal, powersarBsw], section-type=CODE  # Code called with a recurrence of 100us or faster and global scope
    CODE_100US_ASIL_C_LOCAL: memory-allocation-keyword-policy=ADDR-METHOD-SHORT-NAME, options=[safetyAsilC, powersar100us, coreLocal, powersarBsw], section-type=CODE  # Code called with a recurrence of 100us or faster and local scope
    CODE_100US_ASIL_D: memory-allocation-keyword-policy=ADDR-METHOD-SHORT-NAME, options=[powersarAsw, safetyAsilD, powersar100us, coreGlobal, powersarBsw], section-type=CODE  # Code called with a recurrence of 100us or faster and global scope
    CODE_100US_ASIL_D_LOCAL: memory-allocation-keyword-policy=ADDR-METHOD-SHORT-NAME, options=[safetyAsilD, powersar100us, coreLocal, powersarBsw], section-type=CODE  # Code called with a recurrence of 100us or faster and local scope
    CODE_100US_QM: memory-allocation-keyword-policy=ADDR-METHOD-SHORT-NAME, options=[safetyQM, powersarAsw, powersar100us, coreGlobal, powersarBsw], section-type=CODE  # Code called with a recurrence of 100us or faster and global scope
    CODE_100US_QM_LOCAL: memory-allocation-keyword-policy=ADDR-METHOD-SHORT-NAME, options=[safetyQM, powersar100us, coreLocal, powersarBsw], section-type=CODE  # Code called with a recurrence of 100us or faster and local scope
    CODE_10MS_ASIL_A: memory-allocation-keyword-policy=ADDR-METHOD-SHORT-NAME, options=[powersarAsw, safetyAsilA, powersar10ms, coreGlobal, powersarBsw], section-type=CODE  # Code called with a recurrence of 10ms or faster and global scope
    CODE_10MS_ASIL_A_LOCAL: memory-allocation-keyword-policy=ADDR-METHOD-SHORT-NAME, options=[safetyAsilA, powersar10ms, coreLocal, powersarBsw], section-type=CODE  # Code called with a recurrence of 10ms or faster and local scope
    CODE_10MS_ASIL_B: memory-allocation-keyword-policy=ADDR-METHOD-SHORT-NAME, options=[powersarAsw, safetyAsilB, powersar10ms, coreGlobal, powersarBsw], section-type=CODE  # Code called with a recurrence of 10ms or faster and global scope
    CODE_10MS_ASIL_B_LOCAL: memory-allocation-keyword-policy=ADDR-METHOD-SHORT-NAME, options=[safetyAsilB, powersar10ms, coreLocal, powersarBsw], section-type=CODE  # Code called with a recurrence of 10ms or faster and local scope
    CODE_10MS_ASIL_C: memory-allocation-keyword-policy=ADDR-METHOD-SHORT-NAME, options=[safetyAsilC, powersarAsw, powersar10ms, coreGlobal, powersarBsw], section-type=CODE  # Code called with a recurrence of 10ms or faster and global scope
    CODE_10MS_ASIL_C_LOCAL: memory-allocation-keyword-policy=ADDR-METHOD-SHORT-NAME, options=[safetyAsilC, powersar10ms, coreLocal, powersarBsw], section-type=CODE  # Code called with a recurrence of 10ms or faster and local scope
    CODE_10MS_ASIL_D: memory-allocation-keyword-policy=ADDR-METHOD-SHORT-NAME, options=[powersarAsw, safetyAsilD, powersar10ms, coreGlobal, powersarBsw], section-type=CODE  # Code called with a recurrence of 10ms or faster and global scope
    CODE_10MS_ASIL_D_LOCAL: memory-allocation-keyword-policy=ADDR-METHOD-SHORT-NAME, options=[safetyAsilD, powersar10ms, coreLocal, powersarBsw], section-type=CODE  # Code called with a recurrence of 10ms or faster and local scope
    CODE_10MS_QM: memory-allocation-keyword-policy=ADDR-METHOD-SHORT-NAME, options=[safetyQM, powersarAsw, powersar10ms, coreGlobal, powersarBsw], section-type=CODE  # Code called with a recurrence of 10ms or faster and global scope
    CODE_10MS_QM_LOCAL: memory-allocation-keyword-policy=ADDR-METHOD-SHORT-NAME, options=[safetyQM, powersar10ms, coreLocal, powersarBsw], section-type=CODE  # Code called with a recurrence of 10ms or faster and local scope
    CODE_1MS_ASIL_A: memory-allocation-keyword-policy=ADDR-METHOD-SHORT-NAME, options=[powersarAsw, safetyAsilA, powersar1ms, coreGlobal, powersarBsw], section-type=CODE  # Code called with a recurrence of 1ms or faster and global scope
    CODE_1MS_ASIL_A_LOCAL: memory-allocation-keyword-policy=ADDR-METHOD-SHORT-NAME, options=[safetyAsilA, powersar1ms, coreLocal, powersarBsw], section-type=CODE  # Code called with a recurrence of 1ms or faster and local scope
    CODE_1MS_ASIL_B: memory-allocation-keyword-policy=ADDR-METHOD-SHORT-NAME, options=[powersarAsw, safetyAsilB, powersar1ms, coreGlobal, powersarBsw], section-type=CODE  # Code called with a recurrence of 1ms or faster and global scope
    CODE_1MS_ASIL_B_LOCAL: memory-allocation-keyword-policy=ADDR-METHOD-SHORT-NAME, options=[safetyAsilB, powersar1ms, coreLocal, powersarBsw], section-type=CODE  # Code called with a recurrence of 1ms or faster and local scope
    CODE_1MS_ASIL_C: memory-allocation-keyword-policy=ADDR-METHOD-SHORT-NAME, options=[safetyAsilC, powersarAsw, powersar1ms, coreGlobal, powersarBsw], section-type=CODE  # Code called with a recurrence of 1ms or faster and global scope
    CODE_1MS_ASIL_C_LOCAL: memory-allocation-keyword-policy=ADDR-METHOD-SHORT-NAME, options=[safetyAsilC, powersar1ms, coreLocal, powersarBsw], section-type=CODE  # Code called with a recurrence of 1ms or faster and local scope
    CODE_1MS_ASIL_D: memory-allocation-keyword-policy=ADDR-METHOD-SHORT-NAME, options=[powersarAsw, safetyAsilD, powersar1ms, coreGlobal, powersarBsw], section-type=CODE  # Code called with a recurrence of 1ms or faster and global scope
    CODE_1MS_ASIL_D_LOCAL: memory-allocation-keyword-policy=ADDR-METHOD-SHORT-NAME, options=[safetyAsilD, powersar1ms, coreLocal, powersarBsw], section-type=CODE  # Code called with a recurrence of 1ms or faster and local scope
    CODE_1MS_QM: memory-allocation-keyword-policy=ADDR-METHOD-SHORT-NAME, options=[safetyQM, powersarAsw, powersar1ms, coreGlobal, powersarBsw], section-type=CODE  # Code called with a recurrence of 1ms or faster and global scope
    CODE_1MS_QM_LOCAL: memory-allocation-keyword-policy=ADDR-METHOD-SHORT-NAME, options=[safetyQM, powersar1ms, coreLocal, powersarBsw], section-type=CODE  # Code called with a recurrence of 1ms or faster and local scope
    CODE_20MS_ASIL_A: memory-allocation-keyword-policy=ADDR-METHOD-SHORT-NAME, options=[powersarAsw, safetyAsilA, powersar20ms, coreGlobal, powersarBsw], section-type=CODE  # Code called with a recurrence of 20ms or faster and global scope
    CODE_20MS_ASIL_A_LOCAL: memory-allocation-keyword-policy=ADDR-METHOD-SHORT-NAME, options=[safetyAsilA, powersar20ms, coreLocal, powersarBsw], section-type=CODE  # Code called with a recurrence of 20ms or faster and local scope
    CODE_20MS_ASIL_B: memory-allocation-keyword-policy=ADDR-METHOD-SHORT-NAME, options=[powersarAsw, safetyAsilB, powersar20ms, coreGlobal, powersarBsw], section-type=CODE  # Code called with a recurrence of 20ms or faster and global scope
    CODE_20MS_ASIL_B_LOCAL: memory-allocation-keyword-policy=ADDR-METHOD-SHORT-NAME, options=[safetyAsilB, powersar20ms, coreLocal, powersarBsw], section-type=CODE  # Code called with a recurrence of 20ms or faster and local scope
    CODE_20MS_ASIL_C: memory-allocation-keyword-policy=ADDR-METHOD-SHORT-NAME, options=[safetyAsilC, powersarAsw, powersar20ms, coreGlobal, powersarBsw], section-type=CODE  # Code called with a recurrence of 20ms or faster and global scope
    CODE_20MS_ASIL_C_LOCAL: memory-allocation-keyword-policy=ADDR-METHOD-SHORT-NAME, options=[safetyAsilC, powersar20ms, coreLocal, powersarBsw], section-type=CODE  # Code called with a recurrence of 20ms or faster and local scope
    CODE_20MS_ASIL_D: memory-allocation-keyword-policy=ADDR-METHOD-SHORT-NAME, options=[powersarAsw, safetyAsilD, powersar20ms, coreGlobal, powersarBsw], section-type=CODE  # Code called with a recurrence of 20ms or faster and global scope
    CODE_20MS_ASIL_D_LOCAL: memory-allocation-keyword-policy=ADDR-METHOD-SHORT-NAME, options=[safetyAsilD, powersar20ms, coreLocal, powersarBsw], section-type=CODE  # Code called with a recurrence of 20ms or faster and local scope
    CODE_20MS_QM: memory-allocation-keyword-policy=ADDR-METHOD-SHORT-NAME, options=[safetyQM, powersarAsw, powersar20ms, coreGlobal, powersarBsw], section-type=CODE  # Code called with a recurrence of 20ms or faster and global scope
    CODE_20MS_QM_LOCAL: memory-allocation-keyword-policy=ADDR-METHOD-SHORT-NAME, options=[safetyQM, powersar20ms, coreLocal, powersarBsw], section-type=CODE  # Code called with a recurrence of 20ms or faster and local scope
    CODE_400US_ASIL_A: memory-allocation-keyword-policy=ADDR-METHOD-SHORT-NAME, options=[powersarAsw, safetyAsilA, powersar400us, coreGlobal, powersarBsw], section-type=CODE  # Code called with a recurrence of 400us or faster and global scope
    CODE_400US_ASIL_A_LOCAL: memory-allocation-keyword-policy=ADDR-METHOD-SHORT-NAME, options=[safetyAsilA, powersar400us, coreLocal, powersarBsw], section-type=CODE  # Code called with a recurrence of 400us or faster and local scope
    CODE_400US_ASIL_B: memory-allocation-keyword-policy=ADDR-METHOD-SHORT-NAME, options=[powersarAsw, safetyAsilB, powersar400us, coreGlobal, powersarBsw], section-type=CODE  # Code called with a recurrence of 400us or faster and global scope
    CODE_400US_ASIL_B_LOCAL: memory-allocation-keyword-policy=ADDR-METHOD-SHORT-NAME, options=[safetyAsilB, powersar400us, coreLocal, powersarBsw], section-type=CODE  # Code called with a recurrence of 400us or faster and local scope
    CODE_400US_ASIL_C: memory-allocation-keyword-policy=ADDR-METHOD-SHORT-NAME, options=[safetyAsilC, powersarAsw, powersar400us, coreGlobal, powersarBsw], section-type=CODE  # Code called with a recurrence of 400us or faster and global scope
    CODE_400US_ASIL_C_LOCAL: memory-allocation-keyword-policy=ADDR-METHOD-SHORT-NAME, options=[safetyAsilC, powersar400us, coreLocal, powersarBsw], section-type=CODE  # Code called with a recurrence of 400us or faster and local scope
    CODE_400US_ASIL_D: memory-allocation-keyword-policy=ADDR-METHOD-SHORT-NAME, options=[powersarAsw, safetyAsilD, powersar400us, coreGlobal, powersarBsw], section-type=CODE  # Code called with a recurrence of 400us or faster and global scope
    CODE_400US_ASIL_D_LOCAL: memory-allocation-keyword-policy=ADDR-METHOD-SHORT-NAME, options=[safetyAsilD, powersar400us, coreLocal, powersarBsw], section-type=CODE  # Code called with a recurrence of 400us or faster and local scope
    CODE_400US_QM: memory-allocation-keyword-policy=ADDR-METHOD-SHORT-NAME, options=[safetyQM, powersarAsw, powersar400us, coreGlobal, powersarBsw], section-type=CODE  # Code called with a recurrence of 400us or faster and global scope
    CODE_400US_QM_LOCAL: memory-allocation-keyword-policy=ADDR-METHOD-SHORT-NAME, options=[safetyQM, powersar400us, coreLocal, powersarBsw], section-type=CODE  # Code called with a recurrence of 400us or faster and local scope
    CODE_40MS_ASIL_A: memory-allocation-keyword-policy=ADDR-METHOD-SHORT-NAME, options=[powersarAsw, safetyAsilA, powersar40ms, coreGlobal, powersarBsw], section-type=CODE  # Code called with a recurrence of 40ms or faster and global scope
    CODE_40MS_ASIL_A_LOCAL: memory-allocation-keyword-policy=ADDR-METHOD-SHORT-NAME, options=[safetyAsilA, powersar40ms, coreLocal, powersarBsw], section-type=CODE  # Code called with a recurrence of 40ms or faster and local scope
    CODE_40MS_ASIL_B: memory-allocation-keyword-policy=ADDR-METHOD-SHORT-NAME, options=[powersarAsw, safetyAsilB, powersar40ms, coreGlobal, powersarBsw], section-type=CODE  # Code called with a recurrence of 40ms or faster and global scope
    CODE_40MS_ASIL_B_LOCAL: memory-allocation-keyword-policy=ADDR-METHOD-SHORT-NAME, options=[safetyAsilB, powersar40ms, coreLocal, powersarBsw], section-type=CODE  # Code called with a recurrence of 40ms or faster and local scope
    CODE_40MS_ASIL_C: memory-allocation-keyword-policy=ADDR-METHOD-SHORT-NAME, options=[safetyAsilC, powersarAsw, powersar40ms, coreGlobal, powersarBsw], section-type=CODE  # Code called with a recurrence of 40ms or faster and global scope
    CODE_40MS_ASIL_C_LOCAL: memory-allocation-keyword-policy=ADDR-METHOD-SHORT-NAME, options=[safetyAsilC, powersar40ms, coreLocal, powersarBsw], section-type=CODE  # Code called with a recurrence of 40ms or faster and local scope
    CODE_40MS_ASIL_D: memory-allocation-keyword-policy=ADDR-METHOD-SHORT-NAME, options=[powersarAsw, safetyAsilD, powersar40ms, coreGlobal, powersarBsw], section-type=CODE  # Code called with a recurrence of 40ms or faster and global scope
    CODE_40MS_ASIL_D_LOCAL: memory-allocation-keyword-policy=ADDR-METHOD-SHORT-NAME, options=[safetyAsilD, powersar40ms, coreLocal, powersarBsw], section-type=CODE  # Code called with a recurrence of 40ms or faster and local scope
    CODE_40MS_QM: memory-allocation-keyword-policy=ADDR-METHOD-SHORT-NAME, options=[safetyQM, powersarAsw, powersar40ms, coreGlobal, powersarBsw], section-type=CODE  # Code called with a recurrence of 40ms or faster and global scope
    CODE_40MS_QM_LOCAL: memory-allocation-keyword-policy=ADDR-METHOD-SHORT-NAME, options=[safetyQM, powersar40ms, coreLocal, powersarBsw], section-type=CODE  # Code called with a recurrence of 40ms or faster and local scope
    CODE_5MS_ASIL_A: memory-allocation-keyword-policy=ADDR-METHOD-SHORT-NAME, options=[powersarAsw, safetyAsilA, powersar5ms, coreGlobal, powersarBsw], section-type=CODE  # Code called with a recurrence of 5ms or faster and global scope
    CODE_5MS_ASIL_A_LOCAL: memory-allocation-keyword-policy=ADDR-METHOD-SHORT-NAME, options=[safetyAsilA, powersar5ms, coreLocal, powersarBsw], section-type=CODE  # Code called with a recurrence of 5ms or faster and local scope
    CODE_5MS_ASIL_B: memory-allocation-keyword-policy=ADDR-METHOD-SHORT-NAME, options=[powersarAsw, safetyAsilB, powersar5ms, coreGlobal, powersarBsw], section-type=CODE  # Code called with a recurrence of 5ms or faster and global scope
    CODE_5MS_ASIL_B_LOCAL: memory-allocation-keyword-policy=ADDR-METHOD-SHORT-NAME, options=[safetyAsilB, powersar5ms, coreLocal, powersarBsw], section-type=CODE  # Code called with a recurrence of 5ms or faster and local scope
    CODE_5MS_ASIL_C: memory-allocation-keyword-policy=ADDR-METHOD-SHORT-NAME, options=[safetyAsilC, powersarAsw, powersar5ms, coreGlobal, powersarBsw], section-type=CODE  # Code called with a recurrence of 5ms or faster and global scope
    CODE_5MS_ASIL_C_LOCAL: memory-allocation-keyword-policy=ADDR-METHOD-SHORT-NAME, options=[safetyAsilC, powersar5ms, coreLocal, powersarBsw], section-type=CODE  # Code called with a recurrence of 5ms or faster and local scope
    CODE_5MS_ASIL_D: memory-allocation-keyword-policy=ADDR-METHOD-SHORT-NAME, options=[powersarAsw, safetyAsilD, powersar5ms, coreGlobal, powersarBsw], section-type=CODE  # Code called with a recurrence of 5ms or faster and global scope
    CODE_5MS_ASIL_D_LOCAL: memory-allocation-keyword-policy=ADDR-METHOD-SHORT-NAME, options=[safetyAsilD, powersar5ms, coreLocal, powersarBsw], section-type=CODE  # Code called with a recurrence of 5ms or faster and local scope
    CODE_5MS_QM: memory-allocation-keyword-policy=ADDR-METHOD-SHORT-NAME, options=[safetyQM, powersarAsw, powersar5ms, coreGlobal, powersarBsw], section-type=CODE  # Code called with a recurrence of 5ms or faster and global scope
    CODE_5MS_QM_LOCAL: memory-allocation-keyword-policy=ADDR-METHOD-SHORT-NAME, options=[safetyQM, powersar5ms, coreLocal, powersarBsw], section-type=CODE  # Code called with a recurrence of 5ms or faster and local scope
    CODE_CAM_ASIL_A: memory-allocation-keyword-policy=ADDR-METHOD-SHORT-NAME, options=[powersarAsw, safetyAsilA, powersarCam, coreGlobal, powersarBsw], section-type=CODE  # Code called with a recurrence related to camshaft signal and global scope
    CODE_CAM_ASIL_A_LOCAL: memory-allocation-keyword-policy=ADDR-METHOD-SHORT-NAME, options=[safetyAsilA, powersarCam, coreLocal, powersarBsw], section-type=CODE  # Code called with a recurrence related to camshaft signal and local scope
    CODE_CAM_ASIL_B: memory-allocation-keyword-policy=ADDR-METHOD-SHORT-NAME, options=[powersarAsw, safetyAsilB, powersarCam, coreGlobal, powersarBsw], section-type=CODE  # Code called with a recurrence related to camshaft signal and global scope
    CODE_CAM_ASIL_B_LOCAL: memory-allocation-keyword-policy=ADDR-METHOD-SHORT-NAME, options=[safetyAsilB, powersarCam, coreLocal, powersarBsw], section-type=CODE  # Code called with a recurrence related to camshaft signal and local scope
    CODE_CAM_ASIL_C: memory-allocation-keyword-policy=ADDR-METHOD-SHORT-NAME, options=[safetyAsilC, powersarAsw, powersarCam, coreGlobal, powersarBsw], section-type=CODE  # Code called with a recurrence related to camshaft signal and global scope
    CODE_CAM_ASIL_C_LOCAL: memory-allocation-keyword-policy=ADDR-METHOD-SHORT-NAME, options=[safetyAsilC, powersarCam, coreLocal, powersarBsw], section-type=CODE  # Code called with a recurrence related to camshaft signal and local scope
    CODE_CAM_ASIL_D: memory-allocation-keyword-policy=ADDR-METHOD-SHORT-NAME, options=[powersarAsw, safetyAsilD, powersarCam, coreGlobal, powersarBsw], section-type=CODE  # Code called with a recurrence related to camshaft signal and global scope
    CODE_CAM_ASIL_D_LOCAL: memory-allocation-keyword-policy=ADDR-METHOD-SHORT-NAME, options=[safetyAsilD, powersarCam, coreLocal, powersarBsw], section-type=CODE  # Code called with a recurrence related to camshaft signal and local scope
    CODE_CAM_QM: memory-allocation-keyword-policy=ADDR-METHOD-SHORT-NAME, options=[safetyQM, powersarAsw, powersarCam, coreGlobal, powersarBsw], section-type=CODE  # Code called with a recurrence related to camshaft signal and global scope
    CODE_CAM_QM_LOCAL: memory-allocation-keyword-policy=ADDR-METHOD-SHORT-NAME, options=[safetyQM, powersarCam, coreLocal, powersarBsw], section-type=CODE  # Code called with a recurrence related to camshaft signal and local scope
    CODE_CRK_ASIL_A: memory-allocation-keyword-policy=ADDR-METHOD-SHORT-NAME, options=[powersarAsw, safetyAsilA, powersarCrk, coreGlobal, powersarBsw], section-type=CODE  # Code called with a recurrence related to crankshaft signal and global scope
    CODE_CRK_ASIL_A_LOCAL: memory-allocation-keyword-policy=ADDR-METHOD-SHORT-NAME, options=[safetyAsilA, powersarCrk, coreLocal, powersarBsw], section-type=CODE  # Code called with a recurrence related to crankshaft signal and local scope
    CODE_CRK_ASIL_B: memory-allocation-keyword-policy=ADDR-METHOD-SHORT-NAME, options=[powersarAsw, safetyAsilB, powersarCrk, coreGlobal, powersarBsw], section-type=CODE  # Code called with a recurrence related to crankshaft signal and global scope
    CODE_CRK_ASIL_B_LOCAL: memory-allocation-keyword-policy=ADDR-METHOD-SHORT-NAME, options=[safetyAsilB, powersarCrk, coreLocal, powersarBsw], section-type=CODE  # Code called with a recurrence related to crankshaft signal and local scope
    CODE_CRK_ASIL_C: memory-allocation-keyword-policy=ADDR-METHOD-SHORT-NAME, options=[safetyAsilC, powersarAsw, powersarCrk, coreGlobal, powersarBsw], section-type=CODE  # Code called with a recurrence related to crankshaft signal and global scope
    CODE_CRK_ASIL_C_LOCAL: memory-allocation-keyword-policy=ADDR-METHOD-SHORT-NAME, options=[safetyAsilC, powersarCrk, coreLocal, powersarBsw], section-type=CODE  # Code called with a recurrence related to crankshaft signal and local scope
    CODE_CRK_ASIL_D: memory-allocation-keyword-policy=ADDR-METHOD-SHORT-NAME, options=[powersarAsw, safetyAsilD, powersarCrk, coreGlobal, powersarBsw], section-type=CODE  # Code called with a recurrence related to crankshaft signal and global scope
    CODE_CRK_ASIL_D_LOCAL: memory-allocation-keyword-policy=ADDR-METHOD-SHORT-NAME, options=[safetyAsilD, powersarCrk, coreLocal, powersarBsw], section-type=CODE  # Code called with a recurrence related to crankshaft signal and local scope
    CODE_CRK_QM: memory-allocation-keyword-policy=ADDR-METHOD-SHORT-NAME, options=[safetyQM, powersarAsw, powersarCrk, coreGlobal, powersarBsw], section-type=CODE  # Code called with a recurrence related to crankshaft signal and global scope
    CODE_CRK_QM_LOCAL: memory-allocation-keyword-policy=ADDR-METHOD-SHORT-NAME, options=[safetyQM, powersarCrk, coreLocal, powersarBsw], section-type=CODE  # Code called with a recurrence related to crankshaft signal and local scope
    CODE_EXCPN_ASIL_D: memory-allocation-keyword-policy=ADDR-METHOD-SHORT-NAME, options=[safetyAsilD, coreGlobal, powersarBsw, powersarExcpn], section-type=CODE  # Code of exception routines which shall run in exception context
    CODE_EXCPNVCT_ASIL_D: memory-allocation-keyword-policy=ADDR-METHOD-SHORT-NAME, options=[safetyAsilD, coreGlobal, powersarBsw, powersarExcpnVct], section-type=CODE  # Code of exception vector
    CODE_IOHANDLER_ASIL_A: memory-allocation-keyword-policy=ADDR-METHOD-SHORT-NAME, options=[safetyAsilA, coreGlobal, powersarBsw, powersarIoHandler], section-type=CODE  # Code of notification functions called by an interrupt service routine and global scope
    CODE_IOHANDLER_ASIL_A_LOCAL: memory-allocation-keyword-policy=ADDR-METHOD-SHORT-NAME, options=[safetyAsilA, coreLocal, powersarBsw, powersarIoHandler], section-type=CODE  # Code of notification functions called by an interrupt service routine and local scope
    CODE_IOHANDLER_ASIL_B: memory-allocation-keyword-policy=ADDR-METHOD-SHORT-NAME, options=[safetyAsilB, coreGlobal, powersarBsw, powersarIoHandler], section-type=CODE  # Code of notification functions called by an interrupt service routine and global scope
    CODE_IOHANDLER_ASIL_B_LOCAL: memory-allocation-keyword-policy=ADDR-METHOD-SHORT-NAME, options=[safetyAsilB, coreLocal, powersarBsw, powersarIoHandler], section-type=CODE  # Code of notification functions called by an interrupt service routine and local scope
    CODE_IOHANDLER_ASIL_C: memory-allocation-keyword-policy=ADDR-METHOD-SHORT-NAME, options=[safetyAsilC, coreGlobal, powersarBsw, powersarIoHandler], section-type=CODE  # Code of notification functions called by an interrupt service routine and global scope
    CODE_IOHANDLER_ASIL_C_LOCAL: memory-allocation-keyword-policy=ADDR-METHOD-SHORT-NAME, options=[safetyAsilC, coreLocal, powersarBsw, powersarIoHandler], section-type=CODE  # Code of notification functions called by an interrupt service routine and local scope
    CODE_IOHANDLER_ASIL_D: memory-allocation-keyword-policy=ADDR-METHOD-SHORT-NAME, options=[safetyAsilD, coreGlobal, powersarBsw, powersarIoHandler], section-type=CODE  # Code of notification functions called by an interrupt service routine and global scope
    CODE_IOHANDLER_ASIL_D_LOCAL: memory-allocation-keyword-policy=ADDR-METHOD-SHORT-NAME, options=[safetyAsilD, coreLocal, powersarBsw, powersarIoHandler], section-type=CODE  # Code of notification functions called by an interrupt service routine and local scope
    CODE_IOHANDLER_QM: memory-allocation-keyword-policy=ADDR-METHOD-SHORT-NAME, options=[safetyQM, coreGlobal, powersarBsw, powersarIoHandler], section-type=CODE  # Code of notification functions called by an interrupt service routine and global scope
    CODE_IOHANDLER_QM_LOCAL: memory-allocation-keyword-policy=ADDR-METHOD-SHORT-NAME, options=[safetyQM, coreLocal, powersarBsw, powersarIoHandler], section-type=CODE  # Code of notification functions called by an interrupt service routine and local scope
    CODE_IOR_ASIL_C: memory-allocation-keyword-policy=ADDR-METHOD-SHORT-NAME, options=[safetyAsilC, coreGlobal, powersarBsw, powersarIor], section-type=CODE  # Special code which inherits the ASIL context of the caller up to ASIL C (inheritance of rights)
    CODE_IOR_ASIL_D: memory-allocation-keyword-policy=ADDR-METHOD-SHORT-NAME, options=[safetyAsilD, coreGlobal, powersarBsw, powersarIor], section-type=CODE  # Special code which inherits the ASIL context of the caller (inheritance of rights)
    CODE_ISR_ASIL_A: memory-allocation-keyword-policy=ADDR-METHOD-SHORT-NAME, options=[safetyAsilA, coreGlobal, powersarBsw, powersarIsr], section-type=CODE  # Code of interrupt service routines with vector entry and global scope
    CODE_ISR_ASIL_A_LOCAL: memory-allocation-keyword-policy=ADDR-METHOD-SHORT-NAME, options=[safetyAsilA, coreLocal, powersarBsw, powersarIsr], section-type=CODE  # Code of interrupt service routines with vector entry and local scope
    CODE_ISR_ASIL_B: memory-allocation-keyword-policy=ADDR-METHOD-SHORT-NAME, options=[safetyAsilB, coreGlobal, powersarBsw, powersarIsr], section-type=CODE  # Code of interrupt service routines with vector entry and global scope
    CODE_ISR_ASIL_B_LOCAL: memory-allocation-keyword-policy=ADDR-METHOD-SHORT-NAME, options=[safetyAsilB, coreLocal, powersarBsw, powersarIsr], section-type=CODE  # Code of interrupt service routines with vector entry and local scope
    CODE_ISR_ASIL_C: memory-allocation-keyword-policy=ADDR-METHOD-SHORT-NAME, options=[safetyAsilC, coreGlobal, powersarBsw, powersarIsr], section-type=CODE  # Code of interrupt service routines with vector entry and global scope
    CODE_ISR_ASIL_C_LOCAL: memory-allocation-keyword-policy=ADDR-METHOD-SHORT-NAME, options=[safetyAsilC, coreLocal, powersarBsw, powersarIsr], section-type=CODE  # Code of interrupt service routines with vector entry and local scope
    CODE_ISR_ASIL_D: memory-allocation-keyword-policy=ADDR-METHOD-SHORT-NAME, options=[safetyAsilD, coreGlobal, powersarBsw, powersarIsr], section-type=CODE  # Code of interrupt service routines with vector entry and global scope
    CODE_ISR_ASIL_D_LOCAL: memory-allocation-keyword-policy=ADDR-METHOD-SHORT-NAME, options=[safetyAsilD, coreLocal, powersarBsw, powersarIsr], section-type=CODE  # Code of interrupt service routines with vector entry and local scope
    CODE_ISR_QM: memory-allocation-keyword-policy=ADDR-METHOD-SHORT-NAME, options=[safetyQM, coreGlobal, powersarBsw, powersarIsr], section-type=CODE  # Code of interrupt service routines with vector entry and global scope
    CODE_ISR_QM_LOCAL: memory-allocation-keyword-policy=ADDR-METHOD-SHORT-NAME, options=[safetyQM, coreLocal, powersarBsw, powersarIsr], section-type=CODE  # Code of interrupt service routines with vector entry and local scope
    CODE_LABEL: memory-allocation-keyword-policy=ADDR-METHOD-SHORT-NAME, options=[powersarBsw, powersarLabel], section-type=CODE  # Code provided by the locator as label
    CODE_LIB_ASIL_D: memory-allocation-keyword-policy=ADDR-METHOD-SHORT-NAME, options=[safetyAsilD, coreGlobal, powersarBsw, powersarIor], section-type=CODE  # Library code which inherits the ASIL context of the caller (inheritance of rights)
    CODE_PROTECTED_QM: memory-allocation-keyword-policy=ADDR-METHOD-SHORT-NAME, options=[safetyQM, powersarAsw, coreGlobal, powersarBsw, protected], section-type=CODE  # Code to be protected against access from outside the control unit and global scope
    CODE_PROTECTED_QM_LOCAL: memory-allocation-keyword-policy=ADDR-METHOD-SHORT-NAME, options=[safetyQM, coreLocal, powersarBsw, protected], section-type=CODE  # Code to be protected against access from outside the control unit and local scope
    CODE_RWW_ASIL_A: memory-allocation-keyword-policy=ADDR-METHOD-SHORT-NAME, options=[safetyAsilA, coreGlobal, powersarBsw, powersarRww], section-type=CODE  # Code executed while flash is programmed with global scope
    CODE_RWW_ASIL_A_LOCAL: memory-allocation-keyword-policy=ADDR-METHOD-SHORT-NAME, options=[safetyAsilA, coreLocal, powersarBsw, powersarRww], section-type=CODE  # Code executed while flash is programmed with local scope
    CODE_RWW_ASIL_B: memory-allocation-keyword-policy=ADDR-METHOD-SHORT-NAME, options=[safetyAsilB, coreGlobal, powersarBsw, powersarRww], section-type=CODE  # Code executed while flash is programmed with global scope
    CODE_RWW_ASIL_B_LOCAL: memory-allocation-keyword-policy=ADDR-METHOD-SHORT-NAME, options=[safetyAsilB, coreLocal, powersarBsw, powersarRww], section-type=CODE  # Code executed while flash is programmed with local scope
    CODE_RWW_ASIL_C: memory-allocation-keyword-policy=ADDR-METHOD-SHORT-NAME, options=[safetyAsilC, coreGlobal, powersarBsw, powersarRww], section-type=CODE  # Code executed while flash is programmed with global scope
    CODE_RWW_ASIL_C_LOCAL: memory-allocation-keyword-policy=ADDR-METHOD-SHORT-NAME, options=[safetyAsilC, coreLocal, powersarBsw, powersarRww], section-type=CODE  # Code executed while flash is programmed with local scope
    CODE_RWW_ASIL_D: memory-allocation-keyword-policy=ADDR-METHOD-SHORT-NAME, options=[safetyAsilD, coreGlobal, powersarBsw, powersarRww], section-type=CODE  # Code executed while flash is programmed with global scope
    CODE_RWW_ASIL_D_LOCAL: memory-allocation-keyword-policy=ADDR-METHOD-SHORT-NAME, options=[safetyAsilD, coreLocal, powersarBsw, powersarRww], section-type=CODE  # Code executed while flash is programmed with local scope
    CODE_RWW_QM: memory-allocation-keyword-policy=ADDR-METHOD-SHORT-NAME, options=[safetyQM, coreGlobal, powersarBsw, powersarRww], section-type=CODE  # Code executed while flash is programmed with global scope
    CODE_RWW_QM_LOCAL: memory-allocation-keyword-policy=ADDR-METHOD-SHORT-NAME, options=[safetyQM, coreLocal, powersarBsw, powersarRww], section-type=CODE  # Code executed while flash is programmed with local scope
    CODE_SERVICE_ASIL_A: memory-allocation-keyword-policy=ADDR-METHOD-SHORT-NAME, options=[powersarAsw, safetyAsilA, powersarService, coreGlobal, powersarBsw], section-type=CODE  # Code provided as interface operation expected to be called with high frequency and global scope
    CODE_SERVICE_ASIL_A_LOCAL: memory-allocation-keyword-policy=ADDR-METHOD-SHORT-NAME, options=[safetyAsilA, powersarService, coreLocal, powersarBsw], section-type=CODE  # Code provided as interface operation expected to be called with high frequency and local scope
    CODE_SERVICE_ASIL_B: memory-allocation-keyword-policy=ADDR-METHOD-SHORT-NAME, options=[powersarAsw, safetyAsilB, powersarService, coreGlobal, powersarBsw], section-type=CODE  # Code provided as interface operation expected to be called with high frequency and global scope
    CODE_SERVICE_ASIL_B_LOCAL: memory-allocation-keyword-policy=ADDR-METHOD-SHORT-NAME, options=[safetyAsilB, powersarService, coreLocal, powersarBsw], section-type=CODE  # Code provided as interface operation expected to be called with high frequency and local scope
    CODE_SERVICE_ASIL_C: memory-allocation-keyword-policy=ADDR-METHOD-SHORT-NAME, options=[safetyAsilC, powersarAsw, powersarService, coreGlobal, powersarBsw], section-type=CODE  # Code provided as interface operation expected to be called with high frequency and global scope
    CODE_SERVICE_ASIL_C_LOCAL: memory-allocation-keyword-policy=ADDR-METHOD-SHORT-NAME, options=[safetyAsilC, powersarService, coreLocal, powersarBsw], section-type=CODE  # Code provided as interface operation expected to be called with high frequency and local scope
    CODE_SERVICE_ASIL_D: memory-allocation-keyword-policy=ADDR-METHOD-SHORT-NAME, options=[powersarAsw, safetyAsilD, powersarService, coreGlobal, powersarBsw], section-type=CODE  # Code provided as interface operation expected to be called with high frequency and global scope
    CODE_SERVICE_ASIL_D_LOCAL: memory-allocation-keyword-policy=ADDR-METHOD-SHORT-NAME, options=[safetyAsilD, powersarService, coreLocal, powersarBsw], section-type=CODE  # Code provided as interface operation expected to be called with high frequency and local scope
    CODE_SERVICE_QM: memory-allocation-keyword-policy=ADDR-METHOD-SHORT-NAME, options=[safetyQM, powersarAsw, powersarService, coreGlobal, powersarBsw], section-type=CODE  # Code provided as interface operation expected to be called with high frequency and global scope
    CODE_SERVICE_QM_LOCAL: memory-allocation-keyword-policy=ADDR-METHOD-SHORT-NAME, options=[safetyQM, powersarService, coreLocal, powersarBsw], section-type=CODE  # Code provided as interface operation expected to be called with high frequency and local scope
    CODE_SLOW_ASIL_A: memory-allocation-keyword-policy=ADDR-METHOD-SHORT-NAME, options=[powersarAsw, safetyAsilA, powersarSlow, coreGlobal, powersarBsw], section-type=CODE  # Code seldomly called (e.g. sporadic events, recurrence slower than 100ms) and global scope
    CODE_SLOW_ASIL_A_LOCAL: memory-allocation-keyword-policy=ADDR-METHOD-SHORT-NAME, options=[safetyAsilA, powersarSlow, coreLocal, powersarBsw], section-type=CODE  # Code seldomly called (e.g. sporadic events, recurrence slower than 100ms) and local scope
    CODE_SLOW_ASIL_B: memory-allocation-keyword-policy=ADDR-METHOD-SHORT-NAME, options=[powersarAsw, safetyAsilB, powersarSlow, coreGlobal, powersarBsw], section-type=CODE  # Code seldomly called (e.g. sporadic events, recurrence slower than 100ms) and global scope
    CODE_SLOW_ASIL_B_LOCAL: memory-allocation-keyword-policy=ADDR-METHOD-SHORT-NAME, options=[safetyAsilB, powersarSlow, coreLocal, powersarBsw], section-type=CODE  # Code seldomly called (e.g. sporadic events, recurrence slower than 100ms) and local scope
    CODE_SLOW_ASIL_C: memory-allocation-keyword-policy=ADDR-METHOD-SHORT-NAME, options=[safetyAsilC, powersarAsw, powersarSlow, coreGlobal, powersarBsw], section-type=CODE  # Code seldomly called (e.g. sporadic events, recurrence slower than 100ms) and global scope
    CODE_SLOW_ASIL_C_LOCAL: memory-allocation-keyword-policy=ADDR-METHOD-SHORT-NAME, options=[safetyAsilC, powersarSlow, coreLocal, powersarBsw], section-type=CODE  # Code seldomly called (e.g. sporadic events, recurrence slower than 100ms) and local scope
    CODE_SLOW_ASIL_D: memory-allocation-keyword-policy=ADDR-METHOD-SHORT-NAME, options=[powersarAsw, safetyAsilD, powersarSlow, coreGlobal, powersarBsw], section-type=CODE  # Code seldomly called (e.g. sporadic events, recurrence slower than 100ms) and global scope
    CODE_SLOW_ASIL_D_LOCAL: memory-allocation-keyword-policy=ADDR-METHOD-SHORT-NAME, options=[safetyAsilD, powersarSlow, coreLocal, powersarBsw], section-type=CODE  # Code seldomly called (e.g. sporadic events, recurrence slower than 100ms) and local scope
    CODE_SLOW_QM: memory-allocation-keyword-policy=ADDR-METHOD-SHORT-NAME, options=[safetyQM, powersarAsw, powersarSlow, coreGlobal, powersarBsw], section-type=CODE  # Code seldomly called (e.g. sporadic events, recurrence slower than 100ms) and global scope
    CODE_SLOW_QM_LOCAL: memory-allocation-keyword-policy=ADDR-METHOD-SHORT-NAME, options=[safetyQM, powersarSlow, coreLocal, powersarBsw], section-type=CODE  # Code seldomly called (e.g. sporadic events, recurrence slower than 100ms) and local scope
    CONST_100MS_ASIL_A: memory-allocation-keyword-policy=ADDR-METHOD-SHORT-NAME, options=[powersarAsw, safetyAsilA, powersar100ms, coreGlobal, powersarBsw], section-type=CONST  # Constants used with a recurrence of 100ms or faster and global scope
    CONST_100MS_ASIL_A_LOCAL: memory-allocation-keyword-policy=ADDR-METHOD-SHORT-NAME, options=[safetyAsilA, powersar100ms, coreLocal, powersarBsw], section-type=CONST  # Constants used with a recurrence of 100ms or faster and local scope
    CONST_100MS_ASIL_B: memory-allocation-keyword-policy=ADDR-METHOD-SHORT-NAME, options=[powersarAsw, safetyAsilB, powersar100ms, coreGlobal, powersarBsw], section-type=CONST  # Constants used with a recurrence of 100ms or faster and global scope
    CONST_100MS_ASIL_B_LOCAL: memory-allocation-keyword-policy=ADDR-METHOD-SHORT-NAME, options=[safetyAsilB, powersar100ms, coreLocal, powersarBsw], section-type=CONST  # Constants used with a recurrence of 100ms or faster and local scope
    CONST_100MS_ASIL_C: memory-allocation-keyword-policy=ADDR-METHOD-SHORT-NAME, options=[safetyAsilC, powersarAsw, powersar100ms, coreGlobal, powersarBsw], section-type=CONST  # Constants used with a recurrence of 100ms or faster and global scope
    CONST_100MS_ASIL_C_LOCAL: memory-allocation-keyword-policy=ADDR-METHOD-SHORT-NAME, options=[safetyAsilC, powersar100ms, coreLocal, powersarBsw], section-type=CONST  # Constants used with a recurrence of 100ms or faster and local scope
    CONST_100MS_ASIL_D: memory-allocation-keyword-policy=ADDR-METHOD-SHORT-NAME, options=[powersarAsw, safetyAsilD, powersar100ms, coreGlobal, powersarBsw], section-type=CONST  # Constants used with a recurrence of 100ms or faster and global scope
    CONST_100MS_ASIL_D_LOCAL: memory-allocation-keyword-policy=ADDR-METHOD-SHORT-NAME, options=[safetyAsilD, powersar100ms, coreLocal, powersarBsw], section-type=CONST  # Constants used with a recurrence of 100ms or faster and local scope
    CONST_100MS_QM: memory-allocation-keyword-policy=ADDR-METHOD-SHORT-NAME, options=[safetyQM, powersarAsw, powersar100ms, coreGlobal, powersarBsw], section-type=CONST  # Constants used with a recurrence of 100ms or faster and global scope
    CONST_100MS_QM_LOCAL: memory-allocation-keyword-policy=ADDR-METHOD-SHORT-NAME, options=[safetyQM, powersar100ms, coreLocal, powersarBsw], section-type=CONST  # Constants used with a recurrence of 100ms or faster and local scope
    CONST_100US_ASIL_A: memory-allocation-keyword-policy=ADDR-METHOD-SHORT-NAME, options=[powersarAsw, safetyAsilA, powersar100us, coreGlobal, powersarBsw], section-type=CONST  # Constants used with a recurrence of 100us or faster and global scope
    CONST_100US_ASIL_A_LOCAL: memory-allocation-keyword-policy=ADDR-METHOD-SHORT-NAME, options=[safetyAsilA, powersar100us, coreLocal, powersarBsw], section-type=CONST  # Constants used with a recurrence of 100us or faster and local scope
    CONST_100US_ASIL_B: memory-allocation-keyword-policy=ADDR-METHOD-SHORT-NAME, options=[powersarAsw, safetyAsilB, powersar100us, coreGlobal, powersarBsw], section-type=CONST  # Constants used with a recurrence of 100us or faster and global scope
    CONST_100US_ASIL_B_LOCAL: memory-allocation-keyword-policy=ADDR-METHOD-SHORT-NAME, options=[safetyAsilB, powersar100us, coreLocal, powersarBsw], section-type=CONST  # Constants used with a recurrence of 100us or faster and local scope
    CONST_100US_ASIL_C: memory-allocation-keyword-policy=ADDR-METHOD-SHORT-NAME, options=[safetyAsilC, powersarAsw, powersar100us, coreGlobal, powersarBsw], section-type=CONST  # Constants used with a recurrence of 100us or faster and global scope
    CONST_100US_ASIL_C_LOCAL: memory-allocation-keyword-policy=ADDR-METHOD-SHORT-NAME, options=[safetyAsilC, powersar100us, coreLocal, powersarBsw], section-type=CONST  # Constants used with a recurrence of 100us or faster and local scope
    CONST_100US_ASIL_D: memory-allocation-keyword-policy=ADDR-METHOD-SHORT-NAME, options=[powersarAsw, safetyAsilD, powersar100us, coreGlobal, powersarBsw], section-type=CONST  # Constants used with a recurrence of 100us or faster and global scope
    CONST_100US_ASIL_D_LOCAL: memory-allocation-keyword-policy=ADDR-METHOD-SHORT-NAME, options=[safetyAsilD, powersar100us, coreLocal, powersarBsw], section-type=CONST  # Constants used with a recurrence of 100us or faster and local scope
    CONST_100US_QM: memory-allocation-keyword-policy=ADDR-METHOD-SHORT-NAME, options=[safetyQM, powersarAsw, powersar100us, coreGlobal, powersarBsw], section-type=CONST  # Constants used with a recurrence of 100us or faster and global scope
    CONST_100US_QM_LOCAL: memory-allocation-keyword-policy=ADDR-METHOD-SHORT-NAME, options=[safetyQM, powersar100us, coreLocal, powersarBsw], section-type=CONST  # Constants used with a recurrence of 100us or faster and local scope
    CONST_10MS_ASIL_A: memory-allocation-keyword-policy=ADDR-METHOD-SHORT-NAME, options=[powersarAsw, safetyAsilA, powersar10ms, coreGlobal, powersarBsw], section-type=CONST  # Constants used with a recurrence of 10ms or faster and global scope
    CONST_10MS_ASIL_A_LOCAL: memory-allocation-keyword-policy=ADDR-METHOD-SHORT-NAME, options=[safetyAsilA, powersar10ms, coreLocal, powersarBsw], section-type=CONST  # Constants used with a recurrence of 10ms or faster and local scope
    CONST_10MS_ASIL_B: memory-allocation-keyword-policy=ADDR-METHOD-SHORT-NAME, options=[powersarAsw, safetyAsilB, powersar10ms, coreGlobal, powersarBsw], section-type=CONST  # Constants used with a recurrence of 10ms or faster and global scope
    CONST_10MS_ASIL_B_LOCAL: memory-allocation-keyword-policy=ADDR-METHOD-SHORT-NAME, options=[safetyAsilB, powersar10ms, coreLocal, powersarBsw], section-type=CONST  # Constants used with a recurrence of 10ms or faster and local scope
    CONST_10MS_ASIL_C: memory-allocation-keyword-policy=ADDR-METHOD-SHORT-NAME, options=[safetyAsilC, powersarAsw, powersar10ms, coreGlobal, powersarBsw], section-type=CONST  # Constants used with a recurrence of 10ms or faster and global scope
    CONST_10MS_ASIL_C_LOCAL: memory-allocation-keyword-policy=ADDR-METHOD-SHORT-NAME, options=[safetyAsilC, powersar10ms, coreLocal, powersarBsw], section-type=CONST  # Constants used with a recurrence of 10ms or faster and local scope
    CONST_10MS_ASIL_D: memory-allocation-keyword-policy=ADDR-METHOD-SHORT-NAME, options=[powersarAsw, safetyAsilD, powersar10ms, coreGlobal, powersarBsw], section-type=CONST  # Constants used with a recurrence of 10ms or faster and global scope
    CONST_10MS_ASIL_D_LOCAL: memory-allocation-keyword-policy=ADDR-METHOD-SHORT-NAME, options=[safetyAsilD, powersar10ms, coreLocal, powersarBsw], section-type=CONST  # Constants used with a recurrence of 10ms or faster and local scope
    CONST_10MS_QM: memory-allocation-keyword-policy=ADDR-METHOD-SHORT-NAME, options=[safetyQM, powersarAsw, powersar10ms, coreGlobal, powersarBsw], section-type=CONST  # Constants used with a recurrence of 10ms or faster and global scope
    CONST_10MS_QM_LOCAL: memory-allocation-keyword-policy=ADDR-METHOD-SHORT-NAME, options=[safetyQM, powersar10ms, coreLocal, powersarBsw], section-type=CONST  # Constants used with a recurrence of 10ms or faster and local scope
    CONST_1MS_ASIL_A: memory-allocation-keyword-policy=ADDR-METHOD-SHORT-NAME, options=[powersarAsw, safetyAsilA, powersar1ms, coreGlobal, powersarBsw], section-type=CONST  # Constants used with a recurrence of 1ms or faster and global scope
    CONST_1MS_ASIL_A_LOCAL: memory-allocation-keyword-policy=ADDR-METHOD-SHORT-NAME, options=[safetyAsilA, powersar1ms, coreLocal, powersarBsw], section-type=CONST  # Constants used with a recurrence of 1ms or faster and local scope
    CONST_1MS_ASIL_B: memory-allocation-keyword-policy=ADDR-METHOD-SHORT-NAME, options=[powersarAsw, safetyAsilB, powersar1ms, coreGlobal, powersarBsw], section-type=CONST  # Constants used with a recurrence of 1ms or faster and global scope
    CONST_1MS_ASIL_B_LOCAL: memory-allocation-keyword-policy=ADDR-METHOD-SHORT-NAME, options=[safetyAsilB, powersar1ms, coreLocal, powersarBsw], section-type=CONST  # Constants used with a recurrence of 1ms or faster and local scope
    CONST_1MS_ASIL_C: memory-allocation-keyword-policy=ADDR-METHOD-SHORT-NAME, options=[safetyAsilC, powersarAsw, powersar1ms, coreGlobal, powersarBsw], section-type=CONST  # Constants used with a recurrence of 1ms or faster and global scope
    CONST_1MS_ASIL_C_LOCAL: memory-allocation-keyword-policy=ADDR-METHOD-SHORT-NAME, options=[safetyAsilC, powersar1ms, coreLocal, powersarBsw], section-type=CONST  # Constants used with a recurrence of 1ms or faster and local scope
    CONST_1MS_ASIL_D: memory-allocation-keyword-policy=ADDR-METHOD-SHORT-NAME, options=[powersarAsw, safetyAsilD, powersar1ms, coreGlobal, powersarBsw], section-type=CONST  # Constants used with a recurrence of 1ms or faster and global scope
    CONST_1MS_ASIL_D_LOCAL: memory-allocation-keyword-policy=ADDR-METHOD-SHORT-NAME, options=[safetyAsilD, powersar1ms, coreLocal, powersarBsw], section-type=CONST  # Constants used with a recurrence of 1ms or faster and local scope
    CONST_1MS_QM: memory-allocation-keyword-policy=ADDR-METHOD-SHORT-NAME, options=[safetyQM, powersarAsw, powersar1ms, coreGlobal, powersarBsw], section-type=CONST  # Constants used with a recurrence of 1ms or faster and global scope
    CONST_1MS_QM_LOCAL: memory-allocation-keyword-policy=ADDR-METHOD-SHORT-NAME, options=[safetyQM, powersar1ms, coreLocal, powersarBsw], section-type=CONST  # Constants used with a recurrence of 1ms or faster and local scope
    CONST_20MS_ASIL_A: memory-allocation-keyword-policy=ADDR-METHOD-SHORT-NAME, options=[powersarAsw, safetyAsilA, powersar20ms, coreGlobal, powersarBsw], section-type=CONST  # Constants used with a recurrence of 20ms or faster and global scope
    CONST_20MS_ASIL_A_LOCAL: memory-allocation-keyword-policy=ADDR-METHOD-SHORT-NAME, options=[safetyAsilA, powersar20ms, coreLocal, powersarBsw], section-type=CONST  # Constants used with a recurrence of 20ms or faster and local scope
    CONST_20MS_ASIL_B: memory-allocation-keyword-policy=ADDR-METHOD-SHORT-NAME, options=[powersarAsw, safetyAsilB, powersar20ms, coreGlobal, powersarBsw], section-type=CONST  # Constants used with a recurrence of 20ms or faster and global scope
    CONST_20MS_ASIL_B_LOCAL: memory-allocation-keyword-policy=ADDR-METHOD-SHORT-NAME, options=[safetyAsilB, powersar20ms, coreLocal, powersarBsw], section-type=CONST  # Constants used with a recurrence of 20ms or faster and local scope
    CONST_20MS_ASIL_C: memory-allocation-keyword-policy=ADDR-METHOD-SHORT-NAME, options=[safetyAsilC, powersarAsw, powersar20ms, coreGlobal, powersarBsw], section-type=CONST  # Constants used with a recurrence of 20ms or faster and global scope
    CONST_20MS_ASIL_C_LOCAL: memory-allocation-keyword-policy=ADDR-METHOD-SHORT-NAME, options=[safetyAsilC, powersar20ms, coreLocal, powersarBsw], section-type=CONST  # Constants used with a recurrence of 20ms or faster and local scope
    CONST_20MS_ASIL_D: memory-allocation-keyword-policy=ADDR-METHOD-SHORT-NAME, options=[powersarAsw, safetyAsilD, powersar20ms, coreGlobal, powersarBsw], section-type=CONST  # Constants used with a recurrence of 20ms or faster and global scope
    CONST_20MS_ASIL_D_LOCAL: memory-allocation-keyword-policy=ADDR-METHOD-SHORT-NAME, options=[safetyAsilD, powersar20ms, coreLocal, powersarBsw], section-type=CONST  # Constants used with a recurrence of 20ms or faster and local scope
    CONST_20MS_QM: memory-allocation-keyword-policy=ADDR-METHOD-SHORT-NAME, options=[safetyQM, powersarAsw, powersar20ms, coreGlobal, powersarBsw], section-type=CONST  # Constants used with a recurrence of 20ms or faster and global scope
    CONST_20MS_QM_LOCAL: memory-allocation-keyword-policy=ADDR-METHOD-SHORT-NAME, options=[safetyQM, powersar20ms, coreLocal, powersarBsw], section-type=CONST  # Constants used with a recurrence of 20ms or faster and local scope
    CONST_400US_ASIL_A: memory-allocation-keyword-policy=ADDR-METHOD-SHORT-NAME, options=[powersarAsw, safetyAsilA, powersar400us, coreGlobal, powersarBsw], section-type=CONST  # Constants used with a recurrence of 400us or faster and global scope
    CONST_400US_ASIL_A_LOCAL: memory-allocation-keyword-policy=ADDR-METHOD-SHORT-NAME, options=[safetyAsilA, powersar400us, coreLocal, powersarBsw], section-type=CONST  # Constants used with a recurrence of 400us or faster and local scope
    CONST_400US_ASIL_B: memory-allocation-keyword-policy=ADDR-METHOD-SHORT-NAME, options=[powersarAsw, safetyAsilB, powersar400us, coreGlobal, powersarBsw], section-type=CONST  # Constants used with a recurrence of 400us or faster and global scope
    CONST_400US_ASIL_B_LOCAL: memory-allocation-keyword-policy=ADDR-METHOD-SHORT-NAME, options=[safetyAsilB, powersar400us, coreLocal, powersarBsw], section-type=CONST  # Constants used with a recurrence of 400us or faster and local scope
    CONST_400US_ASIL_C: memory-allocation-keyword-policy=ADDR-METHOD-SHORT-NAME, options=[safetyAsilC, powersarAsw, powersar400us, coreGlobal, powersarBsw], section-type=CONST  # Constants used with a recurrence of 400us or faster and global scope
    CONST_400US_ASIL_C_LOCAL: memory-allocation-keyword-policy=ADDR-METHOD-SHORT-NAME, options=[safetyAsilC, powersar400us, coreLocal, powersarBsw], section-type=CONST  # Constants used with a recurrence of 400us or faster and local scope
    CONST_400US_ASIL_D: memory-allocation-keyword-policy=ADDR-METHOD-SHORT-NAME, options=[powersarAsw, safetyAsilD, powersar400us, coreGlobal, powersarBsw], section-type=CONST  # Constants used with a recurrence of 400us or faster and global scope
    CONST_400US_ASIL_D_LOCAL: memory-allocation-keyword-policy=ADDR-METHOD-SHORT-NAME, options=[safetyAsilD, powersar400us, coreLocal, powersarBsw], section-type=CONST  # Constants used with a recurrence of 400us or faster and local scope
    CONST_400US_QM: memory-allocation-keyword-policy=ADDR-METHOD-SHORT-NAME, options=[safetyQM, powersarAsw, powersar400us, coreGlobal, powersarBsw], section-type=CONST  # Constants used with a recurrence of 400us or faster and global scope
    CONST_400US_QM_LOCAL: memory-allocation-keyword-policy=ADDR-METHOD-SHORT-NAME, options=[safetyQM, powersar400us, coreLocal, powersarBsw], section-type=CONST  # Constants used with a recurrence of 400us or faster and local scope
    CONST_40MS_ASIL_A: memory-allocation-keyword-policy=ADDR-METHOD-SHORT-NAME, options=[powersarAsw, safetyAsilA, powersar40ms, coreGlobal, powersarBsw], section-type=CONST  # Constants used with a recurrence of 40ms or faster and global scope
    CONST_40MS_ASIL_A_LOCAL: memory-allocation-keyword-policy=ADDR-METHOD-SHORT-NAME, options=[safetyAsilA, powersar40ms, coreLocal, powersarBsw], section-type=CONST  # Constants used with a recurrence of 40ms or faster and local scope
    CONST_40MS_ASIL_B: memory-allocation-keyword-policy=ADDR-METHOD-SHORT-NAME, options=[powersarAsw, safetyAsilB, powersar40ms, coreGlobal, powersarBsw], section-type=CONST  # Constants used with a recurrence of 40ms or faster and global scope
    CONST_40MS_ASIL_B_LOCAL: memory-allocation-keyword-policy=ADDR-METHOD-SHORT-NAME, options=[safetyAsilB, powersar40ms, coreLocal, powersarBsw], section-type=CONST  # Constants used with a recurrence of 40ms or faster and local scope
    CONST_40MS_ASIL_C: memory-allocation-keyword-policy=ADDR-METHOD-SHORT-NAME, options=[safetyAsilC, powersarAsw, powersar40ms, coreGlobal, powersarBsw], section-type=CONST  # Constants used with a recurrence of 40ms or faster and global scope
    CONST_40MS_ASIL_C_LOCAL: memory-allocation-keyword-policy=ADDR-METHOD-SHORT-NAME, options=[safetyAsilC, powersar40ms, coreLocal, powersarBsw], section-type=CONST  # Constants used with a recurrence of 40ms or faster and local scope
    CONST_40MS_ASIL_D: memory-allocation-keyword-policy=ADDR-METHOD-SHORT-NAME, options=[powersarAsw, safetyAsilD, powersar40ms, coreGlobal, powersarBsw], section-type=CONST  # Constants used with a recurrence of 40ms or faster and global scope
    CONST_40MS_ASIL_D_LOCAL: memory-allocation-keyword-policy=ADDR-METHOD-SHORT-NAME, options=[safetyAsilD, powersar40ms, coreLocal, powersarBsw], section-type=CONST  # Constants used with a recurrence of 40ms or faster and local scope
    CONST_40MS_QM: memory-allocation-keyword-policy=ADDR-METHOD-SHORT-NAME, options=[safetyQM, powersarAsw, powersar40ms, coreGlobal, powersarBsw], section-type=CONST  # Constants used with a recurrence of 40ms or faster and global scope
    CONST_40MS_QM_LOCAL: memory-allocation-keyword-policy=ADDR-METHOD-SHORT-NAME, options=[safetyQM, powersar40ms, coreLocal, powersarBsw], section-type=CONST  # Constants used with a recurrence of 40ms or faster and local scope
    CONST_5MS_ASIL_A: memory-allocation-keyword-policy=ADDR-METHOD-SHORT-NAME, options=[powersarAsw, safetyAsilA, powersar5ms, coreGlobal, powersarBsw], section-type=CONST  # Constants used with a recurrence of 5ms or faster and global scope
    CONST_5MS_ASIL_A_LOCAL: memory-allocation-keyword-policy=ADDR-METHOD-SHORT-NAME, options=[safetyAsilA, powersar5ms, coreLocal, powersarBsw], section-type=CONST  # Constants used with a recurrence of 5ms or faster and local scope
    CONST_5MS_ASIL_B: memory-allocation-keyword-policy=ADDR-METHOD-SHORT-NAME, options=[powersarAsw, safetyAsilB, powersar5ms, coreGlobal, powersarBsw], section-type=CONST  # Constants used with a recurrence of 5ms or faster and global scope
    CONST_5MS_ASIL_B_LOCAL: memory-allocation-keyword-policy=ADDR-METHOD-SHORT-NAME, options=[safetyAsilB, powersar5ms, coreLocal, powersarBsw], section-type=CONST  # Constants used with a recurrence of 5ms or faster and local scope
    CONST_5MS_ASIL_C: memory-allocation-keyword-policy=ADDR-METHOD-SHORT-NAME, options=[safetyAsilC, powersarAsw, powersar5ms, coreGlobal, powersarBsw], section-type=CONST  # Constants used with a recurrence of 5ms or faster and global scope
    CONST_5MS_ASIL_C_LOCAL: memory-allocation-keyword-policy=ADDR-METHOD-SHORT-NAME, options=[safetyAsilC, powersar5ms, coreLocal, powersarBsw], section-type=CONST  # Constants used with a recurrence of 5ms or faster and local scope
    CONST_5MS_ASIL_D: memory-allocation-keyword-policy=ADDR-METHOD-SHORT-NAME, options=[powersarAsw, safetyAsilD, powersar5ms, coreGlobal, powersarBsw], section-type=CONST  # Constants used with a recurrence of 5ms or faster and global scope
    CONST_5MS_ASIL_D_LOCAL: memory-allocation-keyword-policy=ADDR-METHOD-SHORT-NAME, options=[safetyAsilD, powersar5ms, coreLocal, powersarBsw], section-type=CONST  # Constants used with a recurrence of 5ms or faster and local scope
    CONST_5MS_QM: memory-allocation-keyword-policy=ADDR-METHOD-SHORT-NAME, options=[safetyQM, powersarAsw, powersar5ms, coreGlobal, powersarBsw], section-type=CONST  # Constants used with a recurrence of 5ms or faster and global scope
    CONST_5MS_QM_LOCAL: memory-allocation-keyword-policy=ADDR-METHOD-SHORT-NAME, options=[safetyQM, powersar5ms, coreLocal, powersarBsw], section-type=CONST  # Constants used with a recurrence of 5ms or faster and local scope
    CONST_CAM_ASIL_A: memory-allocation-keyword-policy=ADDR-METHOD-SHORT-NAME, options=[powersarAsw, safetyAsilA, powersarCam, coreGlobal, powersarBsw], section-type=CONST  # Constants used with a recurrence according to camshaft signal and global scope
    CONST_CAM_ASIL_A_LOCAL: memory-allocation-keyword-policy=ADDR-METHOD-SHORT-NAME, options=[safetyAsilA, powersarCam, coreLocal, powersarBsw], section-type=CONST  # Constants used with a recurrence according to camshaft signal and local scope
    CONST_CAM_ASIL_B: memory-allocation-keyword-policy=ADDR-METHOD-SHORT-NAME, options=[powersarAsw, safetyAsilB, powersarCam, coreGlobal, powersarBsw], section-type=CONST  # Constants used with a recurrence according to camshaft signal and global scope
    CONST_CAM_ASIL_B_LOCAL: memory-allocation-keyword-policy=ADDR-METHOD-SHORT-NAME, options=[safetyAsilB, powersarCam, coreLocal, powersarBsw], section-type=CONST  # Constants used with a recurrence according to camshaft signal and local scope
    CONST_CAM_ASIL_C: memory-allocation-keyword-policy=ADDR-METHOD-SHORT-NAME, options=[safetyAsilC, powersarAsw, powersarCam, coreGlobal, powersarBsw], section-type=CONST  # Constants used with a recurrence according to camshaft signal and global scope
    CONST_CAM_ASIL_C_LOCAL: memory-allocation-keyword-policy=ADDR-METHOD-SHORT-NAME, options=[safetyAsilC, powersarCam, coreLocal, powersarBsw], section-type=CONST  # Constants used with a recurrence according to camshaft signal and local scope
    CONST_CAM_ASIL_D: memory-allocation-keyword-policy=ADDR-METHOD-SHORT-NAME, options=[powersarAsw, safetyAsilD, powersarCam, coreGlobal, powersarBsw], section-type=CONST  # Constants used with a recurrence according to camshaft signal and global scope
    CONST_CAM_ASIL_D_LOCAL: memory-allocation-keyword-policy=ADDR-METHOD-SHORT-NAME, options=[safetyAsilD, powersarCam, coreLocal, powersarBsw], section-type=CONST  # Constants used with a recurrence according to camshaft signal and local scope
    CONST_CAM_QM: memory-allocation-keyword-policy=ADDR-METHOD-SHORT-NAME, options=[safetyQM, powersarAsw, powersarCam, coreGlobal, powersarBsw], section-type=CONST  # Constants used with a recurrence according to camshaft signal and global scope
    CONST_CAM_QM_LOCAL: memory-allocation-keyword-policy=ADDR-METHOD-SHORT-NAME, options=[safetyQM, powersarCam, coreLocal, powersarBsw], section-type=CONST  # Constants used with a recurrence according to camshaft signal and local scope
    CONST_CLIF_NOCRC_QM: memory-allocation-keyword-policy=ADDR-METHOD-SHORT-NAME, options=[safetyQM, powersarBsw, powersarClif, powersarNocrc], section-type=CONST  # Logistic Information Field used for Customer Logistics
    CONST_CRK_ASIL_A: memory-allocation-keyword-policy=ADDR-METHOD-SHORT-NAME, options=[powersarAsw, safetyAsilA, powersarCrk, coreGlobal, powersarBsw], section-type=CONST  # Constants used with a recurrence according to crankshaft signal and global scope
    CONST_CRK_ASIL_A_LOCAL: memory-allocation-keyword-policy=ADDR-METHOD-SHORT-NAME, options=[safetyAsilA, powersarCrk, coreLocal, powersarBsw], section-type=CONST  # Constants used with a recurrence according to crankshaft signal and local scope
    CONST_CRK_ASIL_B: memory-allocation-keyword-policy=ADDR-METHOD-SHORT-NAME, options=[powersarAsw, safetyAsilB, powersarCrk, coreGlobal, powersarBsw], section-type=CONST  # Constants used with a recurrence according to crankshaft signal and global scope
    CONST_CRK_ASIL_B_LOCAL: memory-allocation-keyword-policy=ADDR-METHOD-SHORT-NAME, options=[safetyAsilB, powersarCrk, coreLocal, powersarBsw], section-type=CONST  # Constants used with a recurrence according to crankshaft signal and local scope
    CONST_CRK_ASIL_C: memory-allocation-keyword-policy=ADDR-METHOD-SHORT-NAME, options=[safetyAsilC, powersarAsw, powersarCrk, coreGlobal, powersarBsw], section-type=CONST  # Constants used with a recurrence according to crankshaft signal and global scope
    CONST_CRK_ASIL_C_LOCAL: memory-allocation-keyword-policy=ADDR-METHOD-SHORT-NAME, options=[safetyAsilC, powersarCrk, coreLocal, powersarBsw], section-type=CONST  # Constants used with a recurrence according to crankshaft signal and local scope
    CONST_CRK_ASIL_D: memory-allocation-keyword-policy=ADDR-METHOD-SHORT-NAME, options=[powersarAsw, safetyAsilD, powersarCrk, coreGlobal, powersarBsw], section-type=CONST  # Constants used with a recurrence according to crankshaft signal and global scope
    CONST_CRK_ASIL_D_LOCAL: memory-allocation-keyword-policy=ADDR-METHOD-SHORT-NAME, options=[safetyAsilD, powersarCrk, coreLocal, powersarBsw], section-type=CONST  # Constants used with a recurrence according to crankshaft signal and local scope
    CONST_CRK_QM: memory-allocation-keyword-policy=ADDR-METHOD-SHORT-NAME, options=[safetyQM, powersarAsw, powersarCrk, coreGlobal, powersarBsw], section-type=CONST  # Constants used with a recurrence according to crankshaft signal and global scope
    CONST_CRK_QM_LOCAL: memory-allocation-keyword-policy=ADDR-METHOD-SHORT-NAME, options=[safetyQM, powersarCrk, coreLocal, powersarBsw], section-type=CONST  # Constants used with a recurrence according to crankshaft signal and local scope
    CONST_EXCPN_ASIL_D: memory-allocation-keyword-policy=ADDR-METHOD-SHORT-NAME, options=[safetyAsilD, coreGlobal, powersarBsw, powersarExcpn], section-type=CONST  # Constants used by exception routines which shall run in exception context
    CONST_EXCPNVCT_ASIL_D: memory-allocation-keyword-policy=ADDR-METHOD-SHORT-NAME, options=[safetyAsilD, coreGlobal, powersarBsw, powersarExcpnVct], section-type=CONST  # Constants allocated inside the exception vector
    CONST_IMG_QM: memory-allocation-keyword-policy=ADDR-METHOD-SHORT-NAME, options=[safetyQM, powersarBsw, powersarImage], section-type=CONST  # Memory images allocated as array or structure
    CONST_IMMUTABLE_COLUMNS_ASIL_D: memory-allocation-keyword-policy=ADDR-METHOD-SHORT-NAME-AND-ALIGNMENT, options=[safetyAsilD, coreGlobal, powersarBsw, powersarMnfImuCol], section-type=CONST  # Binary manifest immutable columns of the software cluster, shall be aligned to 32 bit
    CONST_IMMUTABLE_HEADER_ASIL_D: memory-allocation-keyword-policy=ADDR-METHOD-SHORT-NAME-AND-ALIGNMENT, options=[safetyAsilD, coreGlobal, powersarBsw, powersarMnfImuHdr], section-type=CONST  # Binary manifest immutable header of the software cluster, shall be aligned to 32 bit
    CONST_IOHANDLER_ASIL_A: memory-allocation-keyword-policy=ADDR-METHOD-SHORT-NAME, options=[safetyAsilA, coreGlobal, powersarBsw, powersarIoHandler], section-type=CONST  # Constants used by notification functions with global scope
    CONST_IOHANDLER_ASIL_A_LOCAL: memory-allocation-keyword-policy=ADDR-METHOD-SHORT-NAME, options=[safetyAsilA, coreLocal, powersarBsw, powersarIoHandler], section-type=CONST  # Constants used by notification functions with local scope
    CONST_IOHANDLER_ASIL_B: memory-allocation-keyword-policy=ADDR-METHOD-SHORT-NAME, options=[safetyAsilB, coreGlobal, powersarBsw, powersarIoHandler], section-type=CONST  # Constants used by notification functions with global scope
    CONST_IOHANDLER_ASIL_B_LOCAL: memory-allocation-keyword-policy=ADDR-METHOD-SHORT-NAME, options=[safetyAsilB, coreLocal, powersarBsw, powersarIoHandler], section-type=CONST  # Constants used by notification functions with local scope
    CONST_IOHANDLER_ASIL_C: memory-allocation-keyword-policy=ADDR-METHOD-SHORT-NAME, options=[safetyAsilC, coreGlobal, powersarBsw, powersarIoHandler], section-type=CONST  # Constants used by notification functions with global scope
    CONST_IOHANDLER_ASIL_C_LOCAL: memory-allocation-keyword-policy=ADDR-METHOD-SHORT-NAME, options=[safetyAsilC, coreLocal, powersarBsw, powersarIoHandler], section-type=CONST  # Constants used by notification functions with local scope
    CONST_IOHANDLER_ASIL_D: memory-allocation-keyword-policy=ADDR-METHOD-SHORT-NAME, options=[safetyAsilD, coreGlobal, powersarBsw, powersarIoHandler], section-type=CONST  # Constants used by notification functions with global scope
    CONST_IOHANDLER_ASIL_D_LOCAL: memory-allocation-keyword-policy=ADDR-METHOD-SHORT-NAME, options=[safetyAsilD, coreLocal, powersarBsw, powersarIoHandler], section-type=CONST  # Constants used by notification functions with local scope
    CONST_IOHANDLER_QM: memory-allocation-keyword-policy=ADDR-METHOD-SHORT-NAME, options=[safetyQM, coreGlobal, powersarBsw, powersarIoHandler], section-type=CONST  # Constants used by notification functions with global scope
    CONST_IOHANDLER_QM_LOCAL: memory-allocation-keyword-policy=ADDR-METHOD-SHORT-NAME, options=[safetyQM, coreLocal, powersarBsw, powersarIoHandler], section-type=CONST  # Constants used by notification functions with local scope
    CONST_IOR_ASIL_C: memory-allocation-keyword-policy=ADDR-METHOD-SHORT-NAME, options=[safetyAsilC, coreGlobal, powersarBsw, powersarIor], section-type=CONST  # Special constants used by code which inherits the ASIL context of the caller up to ASIL C (inheritance of rights)
    CONST_IOR_ASIL_D: memory-allocation-keyword-policy=ADDR-METHOD-SHORT-NAME, options=[safetyAsilD, coreGlobal, powersarBsw, powersarIor], section-type=CONST  # Special constants used by code which inherits the ASIL context of the caller (inheritance of rights)
    CONST_ISR_ASIL_A: memory-allocation-keyword-policy=ADDR-METHOD-SHORT-NAME, options=[safetyAsilA, coreGlobal, powersarBsw, powersarIsr], section-type=CONST  # Constants used by an interrupt service routine with vector entry and global scope
    CONST_ISR_ASIL_A_LOCAL: memory-allocation-keyword-policy=ADDR-METHOD-SHORT-NAME, options=[safetyAsilA, coreLocal, powersarBsw, powersarIsr], section-type=CONST  # Constants used by an interrupt service routine with vector entry and local scope
    CONST_ISR_ASIL_B: memory-allocation-keyword-policy=ADDR-METHOD-SHORT-NAME, options=[safetyAsilB, coreGlobal, powersarBsw, powersarIsr], section-type=CONST  # Constants used by an interrupt service routine with vector entry and global scope
    CONST_ISR_ASIL_B_LOCAL: memory-allocation-keyword-policy=ADDR-METHOD-SHORT-NAME, options=[safetyAsilB, coreLocal, powersarBsw, powersarIsr], section-type=CONST  # Constants used by an interrupt service routine with vector entry and local scope
    CONST_ISR_ASIL_C: memory-allocation-keyword-policy=ADDR-METHOD-SHORT-NAME, options=[safetyAsilC, coreGlobal, powersarBsw, powersarIsr], section-type=CONST  # Constants used by an interrupt service routine with vector entry and global scope
    CONST_ISR_ASIL_C_LOCAL: memory-allocation-keyword-policy=ADDR-METHOD-SHORT-NAME, options=[safetyAsilC, coreLocal, powersarBsw, powersarIsr], section-type=CONST  # Constants used by an interrupt service routine with vector entry and local scope
    CONST_ISR_ASIL_D: memory-allocation-keyword-policy=ADDR-METHOD-SHORT-NAME, options=[safetyAsilD, coreGlobal, powersarBsw, powersarIsr], section-type=CONST  # Constants used by an interrupt service routine with vector entry and global scope
    CONST_ISR_ASIL_D_LOCAL: memory-allocation-keyword-policy=ADDR-METHOD-SHORT-NAME, options=[safetyAsilD, coreLocal, powersarBsw, powersarIsr], section-type=CONST  # Constants used by an interrupt service routine with vector entry and local scope
    CONST_ISR_QM: memory-allocation-keyword-policy=ADDR-METHOD-SHORT-NAME, options=[safetyQM, coreGlobal, powersarBsw, powersarIsr], section-type=CONST  # Constants used by an interrupt service routine with vector entry and global scope
    CONST_ISR_QM_LOCAL: memory-allocation-keyword-policy=ADDR-METHOD-SHORT-NAME, options=[safetyQM, coreLocal, powersarBsw, powersarIsr], section-type=CONST  # Constants used by an interrupt service routine with vector entry and local scope
    CONST_LABEL: memory-allocation-keyword-policy=ADDR-METHOD-SHORT-NAME, options=[powersarBsw, powersarLabel], section-type=CONST  # Constants provided by the locator as label
    CONST_LIB_ASIL_D: memory-allocation-keyword-policy=ADDR-METHOD-SHORT-NAME, options=[safetyAsilD, coreGlobal, powersarBsw, powersarIor], section-type=CONST  # Constants used by a library which inherits the ASIL context of the caller (inheritance of rights)
    CONST_LIF_BOOT_QM: memory-allocation-keyword-policy=ADDR-METHOD-SHORT-NAME, options=[safetyQM, powersarBoot, powersarBsw, powersarLif], section-type=CONST  # Logistic Information Field used for boot vector
    CONST_LIF_CRC_QM: memory-allocation-keyword-policy=ADDR-METHOD-SHORT-NAME, options=[safetyQM, powersarBsw, powersarCrc, powersarLif], section-type=CONST  # Logistic Information Field used for symbols where a checksum is required
    CONST_LIF_HWCFG_QM: memory-allocation-keyword-policy=ADDR-METHOD-SHORT-NAME, options=[safetyQM, powersarBsw, powersarHwcfg, powersarLif], section-type=CONST  # Logistic Information Field used for hardware configuration
    CONST_LIF_IFTBL_QM: memory-allocation-keyword-policy=ADDR-METHOD-SHORT-NAME, options=[safetyQM, powersarBsw, powersarIftbl, powersarLif], section-type=CONST  # Logistic Information Field used for interface table between build unit parts
    CONST_LIF_MAPINFO_QM: memory-allocation-keyword-policy=ADDR-METHOD-SHORT-NAME, options=[safetyQM, powersarBsw, powersarLif, powersarMapInfo], section-type=CONST  # Logistic Information Field used for mapping information table
    CONST_LIF_NOCRC_QM: memory-allocation-keyword-policy=ADDR-METHOD-SHORT-NAME, options=[safetyQM, powersarBsw, powersarLif, powersarNocrc], section-type=CONST  # Logistic Information Field used for symbols where a checksum is not required
    CONST_LIF_OVKEY_QM: memory-allocation-keyword-policy=ADDR-METHOD-SHORT-NAME, options=[safetyQM, powersarBsw, powersarLif, powersarOvkey], section-type=CONST  # Logistic Information Field used for invalidation key (overwrite key)
    CONST_LIF_SIG_QM: memory-allocation-keyword-policy=ADDR-METHOD-SHORT-NAME, options=[safetyQM, powersarBsw, powersarLif, powersarSig], section-type=CONST  # Logistic Information Field used for signature
    CONST_LIF_VKEY_QM: memory-allocation-keyword-policy=ADDR-METHOD-SHORT-NAME, options=[safetyQM, powersarBsw, powersarLif, powersarVkey], section-type=CONST  # Logistic Information Field used for validation key
    CONST_MLIF_CRC_QM: memory-allocation-keyword-policy=ADDR-METHOD-SHORT-NAME, options=[safetyQM, powersarBsw, powersarCrc, powersarMlif], section-type=CONST  # Logistic information field used for mapping block content
    CONST_MODIFIABLE_COLUMNS_ASIL_D: memory-allocation-keyword-policy=ADDR-METHOD-SHORT-NAME-AND-ALIGNMENT, options=[safetyAsilD, coreGlobal, powersarBsw, powersarMnfChgCol], section-type=CONST  # Binary manifest modifiable columns of the software cluster, shall be aligned to 32 bit
    CONST_PROTECTED_QM: memory-allocation-keyword-policy=ADDR-METHOD-SHORT-NAME, options=[safetyQM, powersarAsw, coreGlobal, powersarBsw, protected], section-type=CONST  # Constants to be protected against access from outside the control unit and global scope
    CONST_PROTECTED_QM_LOCAL: memory-allocation-keyword-policy=ADDR-METHOD-SHORT-NAME, options=[safetyQM, coreLocal, powersarBsw, protected], section-type=CONST  # Constants to be protected against access from outside the control unit and local scope
    CONST_RWW_ASIL_A: memory-allocation-keyword-policy=ADDR-METHOD-SHORT-NAME, options=[safetyAsilA, coreGlobal, powersarBsw, powersarRww], section-type=CONST  # Constants used while flash is programmed with global scope
    CONST_RWW_ASIL_A_LOCAL: memory-allocation-keyword-policy=ADDR-METHOD-SHORT-NAME, options=[safetyAsilA, coreLocal, powersarBsw, powersarRww], section-type=CONST  # Constants used while flash is programmed with local scope
    CONST_RWW_ASIL_B: memory-allocation-keyword-policy=ADDR-METHOD-SHORT-NAME, options=[safetyAsilB, coreGlobal, powersarBsw, powersarRww], section-type=CONST  # Constants used while flash is programmed with global scope
    CONST_RWW_ASIL_B_LOCAL: memory-allocation-keyword-policy=ADDR-METHOD-SHORT-NAME, options=[safetyAsilB, coreLocal, powersarBsw, powersarRww], section-type=CONST  # Constants used while flash is programmed with local scope
    CONST_RWW_ASIL_C: memory-allocation-keyword-policy=ADDR-METHOD-SHORT-NAME, options=[safetyAsilC, coreGlobal, powersarBsw, powersarRww], section-type=CONST  # Constants used while flash is programmed with global scope
    CONST_RWW_ASIL_C_LOCAL: memory-allocation-keyword-policy=ADDR-METHOD-SHORT-NAME, options=[safetyAsilC, coreLocal, powersarBsw, powersarRww], section-type=CONST  # Constants used while flash is programmed with local scope
    CONST_RWW_ASIL_D: memory-allocation-keyword-policy=ADDR-METHOD-SHORT-NAME, options=[safetyAsilD, coreGlobal, powersarBsw, powersarRww], section-type=CONST  # Constants used while flash is programmed with global scope
    CONST_RWW_ASIL_D_LOCAL: memory-allocation-keyword-policy=ADDR-METHOD-SHORT-NAME, options=[safetyAsilD, coreLocal, powersarBsw, powersarRww], section-type=CONST  # Constants used while flash is programmed with local scope
    CONST_RWW_QM: memory-allocation-keyword-policy=ADDR-METHOD-SHORT-NAME, options=[safetyQM, coreGlobal, powersarBsw, powersarRww], section-type=CONST  # Constants used while flash is programmed with global scope
    CONST_RWW_QM_LOCAL: memory-allocation-keyword-policy=ADDR-METHOD-SHORT-NAME, options=[safetyQM, coreLocal, powersarBsw, powersarRww], section-type=CONST  # Constants used while flash is programmed with local scope
    CONST_SERVICE_ASIL_A: memory-allocation-keyword-policy=ADDR-METHOD-SHORT-NAME, options=[powersarAsw, safetyAsilA, powersarService, coreGlobal, powersarBsw], section-type=CONST  # Constants used by interface operations expected to be called with high frequency and global scope
    CONST_SERVICE_ASIL_A_LOCAL: memory-allocation-keyword-policy=ADDR-METHOD-SHORT-NAME, options=[safetyAsilA, powersarService, coreLocal, powersarBsw], section-type=CONST  # Constants used by interface operations expected to be called with high frequency and local scope
    CONST_SERVICE_ASIL_B: memory-allocation-keyword-policy=ADDR-METHOD-SHORT-NAME, options=[powersarAsw, safetyAsilB, powersarService, coreGlobal, powersarBsw], section-type=CONST  # Constants used by interface operations expected to be called with high frequency and global scope
    CONST_SERVICE_ASIL_B_LOCAL: memory-allocation-keyword-policy=ADDR-METHOD-SHORT-NAME, options=[safetyAsilB, powersarService, coreLocal, powersarBsw], section-type=CONST  # Constants used by interface operations expected to be called with high frequency and local scope
    CONST_SERVICE_ASIL_C: memory-allocation-keyword-policy=ADDR-METHOD-SHORT-NAME, options=[safetyAsilC, powersarAsw, powersarService, coreGlobal, powersarBsw], section-type=CONST  # Constants used by interface operations expected to be called with high frequency and global scope
    CONST_SERVICE_ASIL_C_LOCAL: memory-allocation-keyword-policy=ADDR-METHOD-SHORT-NAME, options=[safetyAsilC, powersarService, coreLocal, powersarBsw], section-type=CONST  # Constants used by interface operations expected to be called with high frequency and local scope
    CONST_SERVICE_ASIL_D: memory-allocation-keyword-policy=ADDR-METHOD-SHORT-NAME, options=[powersarAsw, safetyAsilD, powersarService, coreGlobal, powersarBsw], section-type=CONST  # Constants used by interface operations expected to be called with high frequency and global scope
    CONST_SERVICE_ASIL_D_LOCAL: memory-allocation-keyword-policy=ADDR-METHOD-SHORT-NAME, options=[safetyAsilD, powersarService, coreLocal, powersarBsw], section-type=CONST  # Constants used by interface operations expected to be called with high frequency and local scope
    CONST_SERVICE_QM: memory-allocation-keyword-policy=ADDR-METHOD-SHORT-NAME, options=[safetyQM, powersarAsw, powersarService, coreGlobal, powersarBsw], section-type=CONST  # Constants used by interface operations expected to be called with high frequency and global scope
    CONST_SERVICE_QM_LOCAL: memory-allocation-keyword-policy=ADDR-METHOD-SHORT-NAME, options=[safetyQM, powersarService, coreLocal, powersarBsw], section-type=CONST  # Constants used by interface operations expected to be called with high frequency and local scope
    CONST_SLIF_NOCRC_QM: memory-allocation-keyword-policy=ADDR-METHOD-SHORT-NAME, options=[safetyQM, powersarBsw, powersarNocrc, powersarSlif], section-type=CONST  # Logistic Information Field used for Supplier Logistics
    CONST_SLOW_ASIL_A: memory-allocation-keyword-policy=ADDR-METHOD-SHORT-NAME, options=[powersarAsw, safetyAsilA, powersarSlow, coreGlobal, powersarBsw], section-type=CONST  # Constants seldomly used (e.g. in sporadic events, recurrence slower than 100ms) and global scope
    CONST_SLOW_ASIL_A_LOCAL: memory-allocation-keyword-policy=ADDR-METHOD-SHORT-NAME, options=[safetyAsilA, powersarSlow, coreLocal, powersarBsw], section-type=CONST  # Constants seldomly used (e.g. in sporadic events, recurrence slower than 100ms) and local scope
    CONST_SLOW_ASIL_B: memory-allocation-keyword-policy=ADDR-METHOD-SHORT-NAME, options=[powersarAsw, safetyAsilB, powersarSlow, coreGlobal, powersarBsw], section-type=CONST  # Constants seldomly used (e.g. in sporadic events, recurrence slower than 100ms) and global scope
    CONST_SLOW_ASIL_B_LOCAL: memory-allocation-keyword-policy=ADDR-METHOD-SHORT-NAME, options=[safetyAsilB, powersarSlow, coreLocal, powersarBsw], section-type=CONST  # Constants seldomly used (e.g. in sporadic events, recurrence slower than 100ms) and local scope
    CONST_SLOW_ASIL_C: memory-allocation-keyword-policy=ADDR-METHOD-SHORT-NAME, options=[safetyAsilC, powersarAsw, powersarSlow, coreGlobal, powersarBsw], section-type=CONST  # Constants seldomly used (e.g. in sporadic events, recurrence slower than 100ms) and global scope
    CONST_SLOW_ASIL_C_LOCAL: memory-allocation-keyword-policy=ADDR-METHOD-SHORT-NAME, options=[safetyAsilC, powersarSlow, coreLocal, powersarBsw], section-type=CONST  # Constants seldomly used (e.g. in sporadic events, recurrence slower than 100ms) and local scope
    CONST_SLOW_ASIL_D: memory-allocation-keyword-policy=ADDR-METHOD-SHORT-NAME, options=[powersarAsw, safetyAsilD, powersarSlow, coreGlobal, powersarBsw], section-type=CONST  # Constants seldomly used (e.g. in sporadic events, recurrence slower than 100ms) and global scope
    CONST_SLOW_ASIL_D_LOCAL: memory-allocation-keyword-policy=ADDR-METHOD-SHORT-NAME, options=[safetyAsilD, powersarSlow, coreLocal, powersarBsw], section-type=CONST  # Constants seldomly used (e.g. in sporadic events, recurrence slower than 100ms) and local scope
    CONST_SLOW_QM: memory-allocation-keyword-policy=ADDR-METHOD-SHORT-NAME, options=[safetyQM, powersarAsw, powersarSlow, coreGlobal, powersarBsw], section-type=CONST  # Constants seldomly used (e.g. in sporadic events, recurrence slower than 100ms) and global scope
    CONST_SLOW_QM_LOCAL: memory-allocation-keyword-policy=ADDR-METHOD-SHORT-NAME, options=[safetyQM, powersarSlow, coreLocal, powersarBsw], section-type=CONST  # Constants seldomly used (e.g. in sporadic events, recurrence slower than 100ms) and local scope
    VAR_CLEARED_VAM_BIDIR_ASIL_A: memory-allocation-keyword-policy=ADDR-METHOD-SHORT-NAME, options=[safetyAsilA, coreGlobal, powersarBidir, powersarBsw, powersarVam], section-initialization-policy=CLEARED, section-type=VAR  # Cross VAPP communication area for bidirectional transfer which is initialized by VAPP, but cleared by VAM before
    VAR_CLEARED_VAM_BIDIR_ASIL_B: memory-allocation-keyword-policy=ADDR-METHOD-SHORT-NAME, options=[safetyAsilB, coreGlobal, powersarBidir, powersarBsw, powersarVam], section-initialization-policy=CLEARED, section-type=VAR  # Cross VAPP communication area for bidirectional transfer which is initialized by VAPP, but cleared by VAM before
    VAR_CLEARED_VAM_BIDIR_ASIL_C: memory-allocation-keyword-policy=ADDR-METHOD-SHORT-NAME, options=[safetyAsilC, coreGlobal, powersarBidir, powersarBsw, powersarVam], section-initialization-policy=CLEARED, section-type=VAR  # Cross VAPP communication area for bidirectional transfer which is initialized by VAPP, but cleared by VAM before
    VAR_CLEARED_VAM_BIDIR_ASIL_D: memory-allocation-keyword-policy=ADDR-METHOD-SHORT-NAME, options=[safetyAsilD, coreGlobal, powersarBidir, powersarBsw, powersarVam], section-initialization-policy=CLEARED, section-type=VAR  # Cross VAPP communication area for bidirectional transfer which is initialized by VAPP, but cleared by VAM before
    VAR_CLEARED_VAM_BIDIR_QM: memory-allocation-keyword-policy=ADDR-METHOD-SHORT-NAME, options=[safetyQM, coreGlobal, powersarBidir, powersarBsw, powersarVam], section-initialization-policy=CLEARED, section-type=VAR  # Cross VAPP communication area for bidirectional transfer which is initialized by VAPP, but cleared by VAM before
    VAR_CLEARED_VAM_VAPP2VAM_ASIL_A: memory-allocation-keyword-policy=ADDR-METHOD-SHORT-NAME, options=[safetyAsilA, coreGlobal, powersarBsw, powersarVam, powersarVapp2Vam], section-initialization-policy=CLEARED, section-type=VAR  # Cross VAPP communication area for transfer from VAM2APP to be used in VAPP only (initialized by VAPP, but cleared by VAM)
    VAR_CLEARED_VAM_VAPP2VAM_ASIL_B: memory-allocation-keyword-policy=ADDR-METHOD-SHORT-NAME, options=[safetyAsilB, coreGlobal, powersarBsw, powersarVam, powersarVapp2Vam], section-initialization-policy=CLEARED, section-type=VAR  # Cross VAPP communication area for transfer from VAM2APP to be used in VAPP only (initialized by VAPP, but cleared by VAM)
    VAR_CLEARED_VAM_VAPP2VAM_ASIL_C: memory-allocation-keyword-policy=ADDR-METHOD-SHORT-NAME, options=[safetyAsilC, coreGlobal, powersarBsw, powersarVam, powersarVapp2Vam], section-initialization-policy=CLEARED, section-type=VAR  # Cross VAPP communication area for transfer from VAM2APP to be used in VAPP only (initialized by VAPP, but cleared by VAM)
    VAR_CLEARED_VAM_VAPP2VAM_ASIL_D: memory-allocation-keyword-policy=ADDR-METHOD-SHORT-NAME, options=[safetyAsilD, coreGlobal, powersarBsw, powersarVam, powersarVapp2Vam], section-initialization-policy=CLEARED, section-type=VAR  # Cross VAPP communication area for transfer from VAM2APP to be used in VAPP only (initialized by VAPP, but cleared by VAM)
    VAR_CLEARED_VAM_VAPP2VAM_QM: memory-allocation-keyword-policy=ADDR-METHOD-SHORT-NAME, options=[safetyQM, coreGlobal, powersarBsw, powersarVam, powersarVapp2Vam], section-initialization-policy=CLEARED, section-type=VAR  # Cross VAPP communication area for transfer from VAM2APP to be used in VAPP only (initialized by VAPP, but cleared by VAM)
    VAR_INIT_ADP_ASIL_A: memory-allocation-keyword-policy=ADDR-METHOD-SHORT-NAME, options=[powersarCompoundPrimitive, powersarAdp, powersarAsw, safetyAsilA, coreGlobal], section-initialization-policy=INIT, section-type=VAR  # Initialized variables used for adaptation purpose (self learning) with global scope
    VAR_INIT_ADP_ASIL_B: memory-allocation-keyword-policy=ADDR-METHOD-SHORT-NAME, options=[powersarCompoundPrimitive, powersarAdp, powersarAsw, safetyAsilB, coreGlobal], section-initialization-policy=INIT, section-type=VAR  # Initialized variables used for adaptation purpose (self learning) with global scope
    VAR_INIT_ADP_ASIL_C: memory-allocation-keyword-policy=ADDR-METHOD-SHORT-NAME, options=[powersarCompoundPrimitive, safetyAsilC, powersarAdp, powersarAsw, coreGlobal], section-initialization-policy=INIT, section-type=VAR  # Initialized variables used for adaptation purpose (self learning) with global scope
    VAR_INIT_ADP_ASIL_D: memory-allocation-keyword-policy=ADDR-METHOD-SHORT-NAME, options=[powersarCompoundPrimitive, powersarAdp, powersarAsw, safetyAsilD, coreGlobal], section-initialization-policy=INIT, section-type=VAR  # Initialized variables used for adaptation purpose (self learning) with global scope
    VAR_INIT_ADP_QM: memory-allocation-keyword-policy=ADDR-METHOD-SHORT-NAME, options=[powersarCompoundPrimitive, powersarAdp, safetyQM, powersarAsw, coreGlobal], section-initialization-policy=INIT, section-type=VAR  # Initialized variables used for adaptation purpose (self learning) with global scope
    VAR_INIT_ASIL_A: memory-allocation-keyword-policy=ADDR-METHOD-SHORT-NAME-AND-ALIGNMENT, options=[powersarAsw, safetyAsilA, coreGlobal, powersarBsw], section-initialization-policy=INIT, section-type=VAR  # Initialized variables with global scope
    VAR_INIT_ASIL_A_LOCAL: memory-allocation-keyword-policy=ADDR-METHOD-SHORT-NAME-AND-ALIGNMENT, options=[safetyAsilA, coreLocal, powersarBsw], section-initialization-policy=INIT, section-type=VAR  # Initialized variables with local scope
    VAR_INIT_ASIL_B: memory-allocation-keyword-policy=ADDR-METHOD-SHORT-NAME-AND-ALIGNMENT, options=[powersarAsw, safetyAsilB, coreGlobal, powersarBsw], section-initialization-policy=INIT, section-type=VAR  # Initialized variables with global scope
    VAR_INIT_ASIL_B_LOCAL: memory-allocation-keyword-policy=ADDR-METHOD-SHORT-NAME-AND-ALIGNMENT, options=[safetyAsilB, coreLocal, powersarBsw], section-initialization-policy=INIT, section-type=VAR  # Initialized variables with local scope
    VAR_INIT_ASIL_C: memory-allocation-keyword-policy=ADDR-METHOD-SHORT-NAME-AND-ALIGNMENT, options=[safetyAsilC, powersarAsw, coreGlobal, powersarBsw], section-initialization-policy=INIT, section-type=VAR  # Initialized variables with global scope
    VAR_INIT_ASIL_C_LOCAL: memory-allocation-keyword-policy=ADDR-METHOD-SHORT-NAME-AND-ALIGNMENT, options=[safetyAsilC, coreLocal, powersarBsw], section-initialization-policy=INIT, section-type=VAR  # Initialized variables with local scope
    VAR_INIT_ASIL_D: memory-allocation-keyword-policy=ADDR-METHOD-SHORT-NAME-AND-ALIGNMENT, options=[powersarAsw, safetyAsilD, coreGlobal, powersarBsw], section-initialization-policy=INIT, section-type=VAR  # Initialized variables with global scope
    VAR_INIT_ASIL_D_LOCAL: memory-allocation-keyword-policy=ADDR-METHOD-SHORT-NAME-AND-ALIGNMENT, options=[safetyAsilD, coreLocal, powersarBsw], section-initialization-policy=INIT, section-type=VAR  # Initialized variables with local scope
    VAR_INIT_DMA_ASIL_A: memory-allocation-keyword-policy=ADDR-METHOD-SHORT-NAME, options=[safetyAsilA, coreGlobal, powersarBsw, powersarDma], section-initialization-policy=INIT, section-type=VAR  # Initialized RAM area which shall be accessed by DMA and global scope
    VAR_INIT_DMA_ASIL_B: memory-allocation-keyword-policy=ADDR-METHOD-SHORT-NAME, options=[safetyAsilB, coreGlobal, powersarBsw, powersarDma], section-initialization-policy=INIT, section-type=VAR  # Initialized RAM area which shall be accessed by DMA and global scope
    VAR_INIT_DMA_ASIL_C: memory-allocation-keyword-policy=ADDR-METHOD-SHORT-NAME, options=[safetyAsilC, coreGlobal, powersarBsw, powersarDma], section-initialization-policy=INIT, section-type=VAR  # Initialized RAM area which shall be accessed by DMA and global scope
    VAR_INIT_DMA_ASIL_D: memory-allocation-keyword-policy=ADDR-METHOD-SHORT-NAME, options=[safetyAsilD, coreGlobal, powersarBsw, powersarDma], section-initialization-policy=INIT, section-type=VAR  # Initialized RAM area which shall be accessed by DMA and global scope
    VAR_INIT_DMA_QM: memory-allocation-keyword-policy=ADDR-METHOD-SHORT-NAME, options=[safetyQM, coreGlobal, powersarBsw, powersarDma], section-initialization-policy=INIT, section-type=VAR  # Initialized RAM area which shall be accessed by DMA and global scope
    VAR_INIT_HOST_HOST2HSM_QM: memory-allocation-keyword-policy=ADDR-METHOD-SHORT-NAME, options=[safetyQM, coreGlobal, powersarBsw, powersarHost2Hsm, powersarHsm], section-initialization-policy=INIT, section-type=VAR  # HSM communication area for transfer from HOST to HSM to be used by HOST, initialized by HOST
    VAR_INIT_HOST_HSM2HOST_QM: memory-allocation-keyword-policy=ADDR-METHOD-SHORT-NAME, options=[safetyQM, coreGlobal, powersarBsw, powersarHsm, powersarHsm2Host], section-initialization-policy=INIT, section-type=VAR  # HSM communication area for transfer from HSM to HOST to be used by HOST, initialized by HOST
    VAR_INIT_MCRP_PTLCAL_QM: memory-allocation-keyword-policy=ADDR-METHOD-SHORT-NAME, options=[safetyQM, coreGlobal, powersarBsw, powersarMcrpPtlCal], section-initialization-policy=INIT, section-type=VAR  # Initialized RAM to be used as buffer for partial calibration
    VAR_INIT_PROTECTED_QM: memory-allocation-keyword-policy=ADDR-METHOD-SHORT-NAME, options=[safetyQM, powersarAsw, coreGlobal, powersarBsw, protected], section-initialization-policy=INIT, section-type=VAR  # Initialized variables to be protected against access from outside the control unit with global scope
    VAR_INIT_PROTECTED_QM_LOCAL: memory-allocation-keyword-policy=ADDR-METHOD-SHORT-NAME, options=[safetyQM, coreLocal, powersarBsw, protected], section-initialization-policy=INIT, section-type=VAR  # Initialized variables to be protected against access from outside the control unit with local scope
    VAR_INIT_QM: memory-allocation-keyword-policy=ADDR-METHOD-SHORT-NAME-AND-ALIGNMENT, options=[safetyQM, powersarAsw, coreGlobal, powersarBsw], section-initialization-policy=INIT, section-type=VAR  # Initialized variables with global scope
    VAR_INIT_QM_LOCAL: memory-allocation-keyword-policy=ADDR-METHOD-SHORT-NAME-AND-ALIGNMENT, options=[safetyQM, coreLocal, powersarBsw], section-initialization-policy=INIT, section-type=VAR  # Initialized variables with local scope
    VAR_INIT_SEM_ASIL_A: memory-allocation-keyword-policy=ADDR-METHOD-SHORT-NAME, options=[safetyAsilA, coreGlobal, powersarBsw, powersarSem], section-initialization-policy=INIT, section-type=VAR  # Initialized semaphores with global scope
    VAR_INIT_SEM_ASIL_B: memory-allocation-keyword-policy=ADDR-METHOD-SHORT-NAME, options=[safetyAsilB, coreGlobal, powersarBsw, powersarSem], section-initialization-policy=INIT, section-type=VAR  # Initialized semaphores with global scope
    VAR_INIT_SEM_ASIL_C: memory-allocation-keyword-policy=ADDR-METHOD-SHORT-NAME, options=[safetyAsilC, coreGlobal, powersarBsw, powersarSem], section-initialization-policy=INIT, section-type=VAR  # Initialized semaphores with global scope
    VAR_INIT_SEM_ASIL_D: memory-allocation-keyword-policy=ADDR-METHOD-SHORT-NAME, options=[safetyAsilD, coreGlobal, powersarBsw, powersarSem], section-initialization-policy=INIT, section-type=VAR  # Initialized semaphores with global scope
    VAR_INIT_SEM_QM: memory-allocation-keyword-policy=ADDR-METHOD-SHORT-NAME, options=[safetyQM, coreGlobal, powersarBsw, powersarSem], section-initialization-policy=INIT, section-type=VAR  # Initialized semaphores with global scope
    VAR_INIT_SYSCTRL_ASIL_C: memory-allocation-keyword-policy=ADDR-METHOD-SHORT-NAME, options=[safetyAsilC, coreGlobal, powersarBsw, powersarSysCtrl], section-initialization-policy=INIT, section-type=VAR  # Special initialized variables used for system control purpose to support ASIL_C IOR
    VAR_INIT_SYSCTRL_ASIL_D: memory-allocation-keyword-policy=ADDR-METHOD-SHORT-NAME, options=[safetyAsilD, coreGlobal, powersarBsw, powersarSysCtrl], section-initialization-policy=INIT, section-type=VAR  # Special initialized variables used for system control purpose in context of interrupts or OS
    VAR_INIT_VAM_BIDIR_ASIL_A: memory-allocation-keyword-policy=ADDR-METHOD-SHORT-NAME, options=[safetyAsilA, coreGlobal, powersarBidir, powersarBsw, powersarVam], section-initialization-policy=INIT, section-type=VAR  # Cross VAPP communication area for bidirectional transfer to be initialized by VAM only
    VAR_INIT_VAM_BIDIR_ASIL_B: memory-allocation-keyword-policy=ADDR-METHOD-SHORT-NAME, options=[safetyAsilB, coreGlobal, powersarBidir, powersarBsw, powersarVam], section-initialization-policy=INIT, section-type=VAR  # Cross VAPP communication area for bidirectional transfer to be initialized by VAM only
    VAR_INIT_VAM_BIDIR_ASIL_C: memory-allocation-keyword-policy=ADDR-METHOD-SHORT-NAME, options=[safetyAsilC, coreGlobal, powersarBidir, powersarBsw, powersarVam], section-initialization-policy=INIT, section-type=VAR  # Cross VAPP communication area for bidirectional transfer to be initialized by VAM only
    VAR_INIT_VAM_BIDIR_ASIL_D: memory-allocation-keyword-policy=ADDR-METHOD-SHORT-NAME, options=[safetyAsilD, coreGlobal, powersarBidir, powersarBsw, powersarVam], section-initialization-policy=INIT, section-type=VAR  # Cross VAPP communication area for bidirectional transfer to be initialized by VAM only
    VAR_INIT_VAM_BIDIR_QM: memory-allocation-keyword-policy=ADDR-METHOD-SHORT-NAME, options=[safetyQM, coreGlobal, powersarBidir, powersarBsw, powersarVam], section-initialization-policy=INIT, section-type=VAR  # Cross VAPP communication area for bidirectional transfer to be initialized by VAM only
    VAR_INIT_VAM_VAM2VAPP_ASIL_A: memory-allocation-keyword-policy=ADDR-METHOD-SHORT-NAME, options=[safetyAsilA, coreGlobal, powersarBsw, powersarVam, powersarVam2Vapp], section-initialization-policy=INIT, section-type=VAR  # Cross VAPP communication area for transfer from VAM2APP to be used in VAM only
    VAR_INIT_VAM_VAM2VAPP_ASIL_B: memory-allocation-keyword-policy=ADDR-METHOD-SHORT-NAME, options=[safetyAsilB, coreGlobal, powersarBsw, powersarVam, powersarVam2Vapp], section-initialization-policy=INIT, section-type=VAR  # Cross VAPP communication area for transfer from VAM2APP to be used in VAM only
    VAR_INIT_VAM_VAM2VAPP_ASIL_C: memory-allocation-keyword-policy=ADDR-METHOD-SHORT-NAME, options=[safetyAsilC, coreGlobal, powersarBsw, powersarVam, powersarVam2Vapp], section-initialization-policy=INIT, section-type=VAR  # Cross VAPP communication area for transfer from VAM2APP to be used in VAM only
    VAR_INIT_VAM_VAM2VAPP_ASIL_D: memory-allocation-keyword-policy=ADDR-METHOD-SHORT-NAME, options=[safetyAsilD, coreGlobal, powersarBsw, powersarVam, powersarVam2Vapp], section-initialization-policy=INIT, section-type=VAR  # Cross VAPP communication area for transfer from VAM2APP to be used in VAM only
    VAR_INIT_VAM_VAM2VAPP_QM: memory-allocation-keyword-policy=ADDR-METHOD-SHORT-NAME, options=[safetyQM, coreGlobal, powersarBsw, powersarVam, powersarVam2Vapp], section-initialization-policy=INIT, section-type=VAR  # Cross VAPP communication area for transfer from VAM2APP to be used in VAM only
    VAR_INIT_VAPP_BIDIR_ASIL_A: memory-allocation-keyword-policy=ADDR-METHOD-SHORT-NAME, options=[safetyAsilA, coreGlobal, powersarBidir, powersarBsw, powersarVapp], section-initialization-policy=INIT, section-type=VAR  # Cross VAPP communication area for bidirectional transfer to be initialized by VAPP only
    VAR_INIT_VAPP_BIDIR_ASIL_B: memory-allocation-keyword-policy=ADDR-METHOD-SHORT-NAME, options=[safetyAsilB, coreGlobal, powersarBidir, powersarBsw, powersarVapp], section-initialization-policy=INIT, section-type=VAR  # Cross VAPP communication area for bidirectional transfer to be initialized by VAPP only
    VAR_INIT_VAPP_BIDIR_ASIL_C: memory-allocation-keyword-policy=ADDR-METHOD-SHORT-NAME, options=[safetyAsilC, coreGlobal, powersarBidir, powersarBsw, powersarVapp], section-initialization-policy=INIT, section-type=VAR  # Cross VAPP communication area for bidirectional transfer to be initialized by VAPP only
    VAR_INIT_VAPP_BIDIR_ASIL_D: memory-allocation-keyword-policy=ADDR-METHOD-SHORT-NAME, options=[safetyAsilD, coreGlobal, powersarBidir, powersarBsw, powersarVapp], section-initialization-policy=INIT, section-type=VAR  # Cross VAPP communication area for bidirectional transfer to be initialized by VAPP only
    VAR_INIT_VAPP_BIDIR_QM: memory-allocation-keyword-policy=ADDR-METHOD-SHORT-NAME, options=[safetyQM, coreGlobal, powersarBidir, powersarBsw, powersarVapp], section-initialization-policy=INIT, section-type=VAR  # Cross VAPP communication area for bidirectional transfer to be initialized by VAPP only
    VAR_INIT_VAPP_VAPP2VAM_ASIL_A: memory-allocation-keyword-policy=ADDR-METHOD-SHORT-NAME, options=[safetyAsilA, coreGlobal, powersarBsw, powersarVapp, powersarVapp2Vam], section-initialization-policy=INIT, section-type=VAR  # Cross VAPP communication area for transfer from VAPP2VAM to be used in VAPP only
    VAR_INIT_VAPP_VAPP2VAM_ASIL_B: memory-allocation-keyword-policy=ADDR-METHOD-SHORT-NAME, options=[safetyAsilB, coreGlobal, powersarBsw, powersarVapp, powersarVapp2Vam], section-initialization-policy=INIT, section-type=VAR  # Cross VAPP communication area for transfer from VAPP2VAM to be used in VAPP only
    VAR_INIT_VAPP_VAPP2VAM_ASIL_C: memory-allocation-keyword-policy=ADDR-METHOD-SHORT-NAME, options=[safetyAsilC, coreGlobal, powersarBsw, powersarVapp, powersarVapp2Vam], section-initialization-policy=INIT, section-type=VAR  # Cross VAPP communication area for transfer from VAPP2VAM to be used in VAPP only
    VAR_INIT_VAPP_VAPP2VAM_ASIL_D: memory-allocation-keyword-policy=ADDR-METHOD-SHORT-NAME, options=[safetyAsilD, coreGlobal, powersarBsw, powersarVapp, powersarVapp2Vam], section-initialization-policy=INIT, section-type=VAR  # Cross VAPP communication area for transfer from VAPP2VAM to be used in VAPP only
    VAR_INIT_VAPP_VAPP2VAM_QM: memory-allocation-keyword-policy=ADDR-METHOD-SHORT-NAME, options=[safetyQM, coreGlobal, powersarBsw, powersarVapp, powersarVapp2Vam], section-initialization-policy=INIT, section-type=VAR  # Cross VAPP communication area for transfer from VAPP2VAM to be used in VAPP only
    VAR_LABEL: memory-allocation-keyword-policy=ADDR-METHOD-SHORT-NAME, options=[powersarBsw, powersarLabel], section-initialization-policy=INIT, section-type=VAR  # Variables provided by the locator as label
    VAR_NO_INIT_ASIL_A: memory-allocation-keyword-policy=ADDR-METHOD-SHORT-NAME, options=[resetSafe, powersarAsw, safetyAsilA, coreGlobal, powersarBsw], section-initialization-policy=NO-INIT, section-type=VAR  # Reset safe variables with global scope
    VAR_NO_INIT_ASIL_B: memory-allocation-keyword-policy=ADDR-METHOD-SHORT-NAME, options=[resetSafe, powersarAsw, safetyAsilB, coreGlobal, powersarBsw], section-initialization-policy=NO-INIT, section-type=VAR  # Reset safe variables with global scope
    VAR_NO_INIT_ASIL_C: memory-allocation-keyword-policy=ADDR-METHOD-SHORT-NAME, options=[resetSafe, safetyAsilC, powersarAsw, coreGlobal, powersarBsw], section-initialization-policy=NO-INIT, section-type=VAR  # Reset safe variables with global scope
    VAR_NO_INIT_ASIL_D: memory-allocation-keyword-policy=ADDR-METHOD-SHORT-NAME, options=[resetSafe, powersarAsw, safetyAsilD, coreGlobal, powersarBsw], section-initialization-policy=NO-INIT, section-type=VAR  # Reset safe variables with global scope
    VAR_NO_INIT_LIF_BCRAM_QM: memory-allocation-keyword-policy=ADDR-METHOD-SHORT-NAME, options=[safetyQM, powersarBcram, powersarBsw, powersarLif], section-initialization-policy=NO-INIT, section-type=VAR  # Reset safe Logistic Information Field used for transferring data between build units
    VAR_NO_INIT_LIF_MAPINFO_QM: memory-allocation-keyword-policy=ADDR-METHOD-SHORT-NAME, options=[safetyQM, powersarBsw, powersarLif, powersarMapInfo], section-initialization-policy=NO-INIT, section-type=VAR  # Reset safe Logistic Information Field used for mapping information table
    VAR_NO_INIT_MCRPC_QM: memory-allocation-keyword-policy=ADDR-METHOD-SHORT-NAME, options=[resetSafe, safetyQM, coreGlobal, powersarBsw, powersarMcrpC], section-initialization-policy=NO-INIT, section-type=VAR  # Reset safe variables for measurement purpose with global scope
    VAR_NO_INIT_MCRPM_QM: memory-allocation-keyword-policy=ADDR-METHOD-SHORT-NAME, options=[resetSafe, safetyQM, coreGlobal, powersarBsw, powersarMcrpM], section-initialization-policy=NO-INIT, section-type=VAR  # Reset safe variables for calibration purpose with global scope
    VAR_NO_INIT_MCRPP_QM: memory-allocation-keyword-policy=ADDR-METHOD-SHORT-NAME, options=[resetSafe, safetyQM, coreGlobal, powersarBsw, powersarMcrpP], section-initialization-policy=NO-INIT, section-type=VAR  # Reset safe variables for programming purpose with global scope
    VAR_NO_INIT_MCRPR_QM: memory-allocation-keyword-policy=ADDR-METHOD-SHORT-NAME, options=[resetSafe, safetyQM, coreGlobal, powersarBsw, powersarMcrpR], section-initialization-policy=NO-INIT, section-type=VAR  # Reset safe variables for rapid prototyping with global scope
    VAR_NO_INIT_NV_ADP_ASIL_A: memory-allocation-keyword-policy=ADDR-METHOD-SHORT-NAME, options=[nvData, powersarCompoundPrimitive, powersarAdp, powersarAsw, safetyAsilA, coreGlobal], section-initialization-policy=NO-INIT, section-type=VAR  # Non volatile variables stored reset safe used for adaptation purpose (self learning) with global scope
    VAR_NO_INIT_NV_ADP_ASIL_B: memory-allocation-keyword-policy=ADDR-METHOD-SHORT-NAME, options=[nvData, powersarCompoundPrimitive, powersarAdp, powersarAsw, safetyAsilB, coreGlobal], section-initialization-policy=NO-INIT, section-type=VAR  # Non volatile variables stored reset safe used for adaptation purpose (self learning) with global scope
    VAR_NO_INIT_NV_ADP_ASIL_C: memory-allocation-keyword-policy=ADDR-METHOD-SHORT-NAME, options=[nvData, powersarCompoundPrimitive, safetyAsilC, powersarAdp, powersarAsw, coreGlobal], section-initialization-policy=NO-INIT, section-type=VAR  # Non volatile variables stored reset safe used for adaptation purpose (self learning) with global scope
    VAR_NO_INIT_NV_ADP_ASIL_D: memory-allocation-keyword-policy=ADDR-METHOD-SHORT-NAME, options=[nvData, powersarCompoundPrimitive, powersarAdp, powersarAsw, safetyAsilD, coreGlobal], section-initialization-policy=NO-INIT, section-type=VAR  # Non volatile variables stored reset safe used for adaptation purpose (self learning) with global scope
    VAR_NO_INIT_NV_ADP_QM: memory-allocation-keyword-policy=ADDR-METHOD-SHORT-NAME, options=[nvData, powersarCompoundPrimitive, powersarAdp, safetyQM, powersarAsw, coreGlobal], section-initialization-policy=NO-INIT, section-type=VAR  # Non volatile variables stored reset safe used for adaptation purpose (self learning) with global scope
    VAR_NO_INIT_NV_ASIL_A: memory-allocation-keyword-policy=ADDR-METHOD-SHORT-NAME, options=[nvData, powersarAsw, safetyAsilA, coreGlobal, powersarBsw], section-initialization-policy=NO-INIT, section-type=VAR  # Non volatile variables stored reset safe with global scope
    VAR_NO_INIT_NV_ASIL_B: memory-allocation-keyword-policy=ADDR-METHOD-SHORT-NAME, options=[nvData, powersarAsw, safetyAsilB, coreGlobal, powersarBsw], section-initialization-policy=NO-INIT, section-type=VAR  # Non volatile variables stored reset safe with global scope
    VAR_NO_INIT_NV_ASIL_C: memory-allocation-keyword-policy=ADDR-METHOD-SHORT-NAME, options=[nvData, safetyAsilC, powersarAsw, coreGlobal, powersarBsw], section-initialization-policy=NO-INIT, section-type=VAR  # Non volatile variables stored reset safe with global scope
    VAR_NO_INIT_NV_ASIL_D: memory-allocation-keyword-policy=ADDR-METHOD-SHORT-NAME, options=[nvData, powersarAsw, safetyAsilD, coreGlobal, powersarBsw], section-initialization-policy=NO-INIT, section-type=VAR  # Non volatile variables stored reset safe with global scope
    VAR_NO_INIT_NV_QM: memory-allocation-keyword-policy=ADDR-METHOD-SHORT-NAME, options=[nvData, safetyQM, powersarAsw, coreGlobal, powersarBsw], section-initialization-policy=NO-INIT, section-type=VAR  # Non volatile variables stored reset safe with global scope
    VAR_NO_INIT_PROTECTED_QM: memory-allocation-keyword-policy=ADDR-METHOD-SHORT-NAME, options=[resetSafe, safetyQM, powersarAsw, coreGlobal, powersarBsw, protected], section-initialization-policy=NO-INIT, section-type=VAR  # Reset safe variables to be protected against access from outside the control unit with global scope
    VAR_NO_INIT_QM: memory-allocation-keyword-policy=ADDR-METHOD-SHORT-NAME, options=[resetSafe, safetyQM, powersarAsw, coreGlobal, powersarBsw], section-initialization-policy=NO-INIT, section-type=VAR  # Reset safe variables with global scope
    VAR_NO_INIT_VAPP_BIDIR_ASIL_A: memory-allocation-keyword-policy=ADDR-METHOD-SHORT-NAME, options=[safetyAsilA, coreGlobal, powersarBidir, powersarBsw, powersarVapp], section-initialization-policy=NO-INIT, section-type=VAR  # Cross VAPP communication area for bidirectional transfer which is not initialized by VAPP
    VAR_NO_INIT_VAPP_BIDIR_ASIL_B: memory-allocation-keyword-policy=ADDR-METHOD-SHORT-NAME, options=[safetyAsilB, coreGlobal, powersarBidir, powersarBsw, powersarVapp], section-initialization-policy=NO-INIT, section-type=VAR  # Cross VAPP communication area for bidirectional transfer which is not initialized by VAPP
    VAR_NO_INIT_VAPP_BIDIR_ASIL_C: memory-allocation-keyword-policy=ADDR-METHOD-SHORT-NAME, options=[safetyAsilC, coreGlobal, powersarBidir, powersarBsw, powersarVapp], section-initialization-policy=NO-INIT, section-type=VAR  # Cross VAPP communication area for bidirectional transfer which is not initialized by VAPP
    VAR_NO_INIT_VAPP_BIDIR_ASIL_D: memory-allocation-keyword-policy=ADDR-METHOD-SHORT-NAME, options=[safetyAsilD, coreGlobal, powersarBidir, powersarBsw, powersarVapp], section-initialization-policy=NO-INIT, section-type=VAR  # Cross VAPP communication area for bidirectional transfer which is not initialized by VAPP
    VAR_NO_INIT_VAPP_BIDIR_QM: memory-allocation-keyword-policy=ADDR-METHOD-SHORT-NAME, options=[safetyQM, coreGlobal, powersarBidir, powersarBsw, powersarVapp], section-initialization-policy=NO-INIT, section-type=VAR  # Cross VAPP communication area for bidirectional transfer which is not initialized by VAPP
    VAR_NO_INIT_VAPP_VAM2VAPP_ASIL_A: memory-allocation-keyword-policy=ADDR-METHOD-SHORT-NAME, options=[safetyAsilA, coreGlobal, powersarBsw, powersarVam2Vapp, powersarVapp], section-initialization-policy=NO-INIT, section-type=VAR  # Cross VAPP communication area for transfer from VAM2VAPP to be used in VAPP only, but not initialized by VAPP
    VAR_NO_INIT_VAPP_VAM2VAPP_ASIL_B: memory-allocation-keyword-policy=ADDR-METHOD-SHORT-NAME, options=[safetyAsilB, coreGlobal, powersarBsw, powersarVam2Vapp, powersarVapp], section-initialization-policy=NO-INIT, section-type=VAR  # Cross VAPP communication area for transfer from VAM2VAPP to be used in VAPP only, but not initialized by VAPP
    VAR_NO_INIT_VAPP_VAM2VAPP_ASIL_C: memory-allocation-keyword-policy=ADDR-METHOD-SHORT-NAME, options=[safetyAsilC, coreGlobal, powersarBsw, powersarVam2Vapp, powersarVapp], section-initialization-policy=NO-INIT, section-type=VAR  # Cross VAPP communication area for transfer from VAM2VAPP to be used in VAPP only, but not initialized by VAPP
    VAR_NO_INIT_VAPP_VAM2VAPP_ASIL_D: memory-allocation-keyword-policy=ADDR-METHOD-SHORT-NAME, options=[safetyAsilD, coreGlobal, powersarBsw, powersarVam2Vapp, powersarVapp], section-initialization-policy=NO-INIT, section-type=VAR  # Cross VAPP communication area for transfer from VAM2VAPP to be used in VAPP only, but not initialized by VAPP
    VAR_NO_INIT_VAPP_VAM2VAPP_QM: memory-allocation-keyword-policy=ADDR-METHOD-SHORT-NAME, options=[safetyQM, coreGlobal, powersarBsw, powersarVam2Vapp, powersarVapp], section-initialization-policy=NO-INIT, section-type=VAR  # Cross VAPP communication area for transfer from VAM2VAPP to be used in VAPP only, but not initialized by VAPP
package /Continental_08/PowerSAR/ConfigData/SwSystemConstantValueSets
  sw systemconstant value set DefaultSwSystemconstantValueSet: sw-systemconst-value{sw-systemconst=ScNrByteBufFrfDem, value=1}
package /AUTOSAR_GenDef/ImplementationDataTypes
  impl type ConstVoidPtr: category=DATA_REFERENCE, sw-pointer-target-props={target-category=VALUE, base-type=void, sw-impl-policy=CONST}
  impl type VoidPtr: category=DATA_REFERENCE, sw-pointer-target-props={target-category=VALUE, base-type=void}
